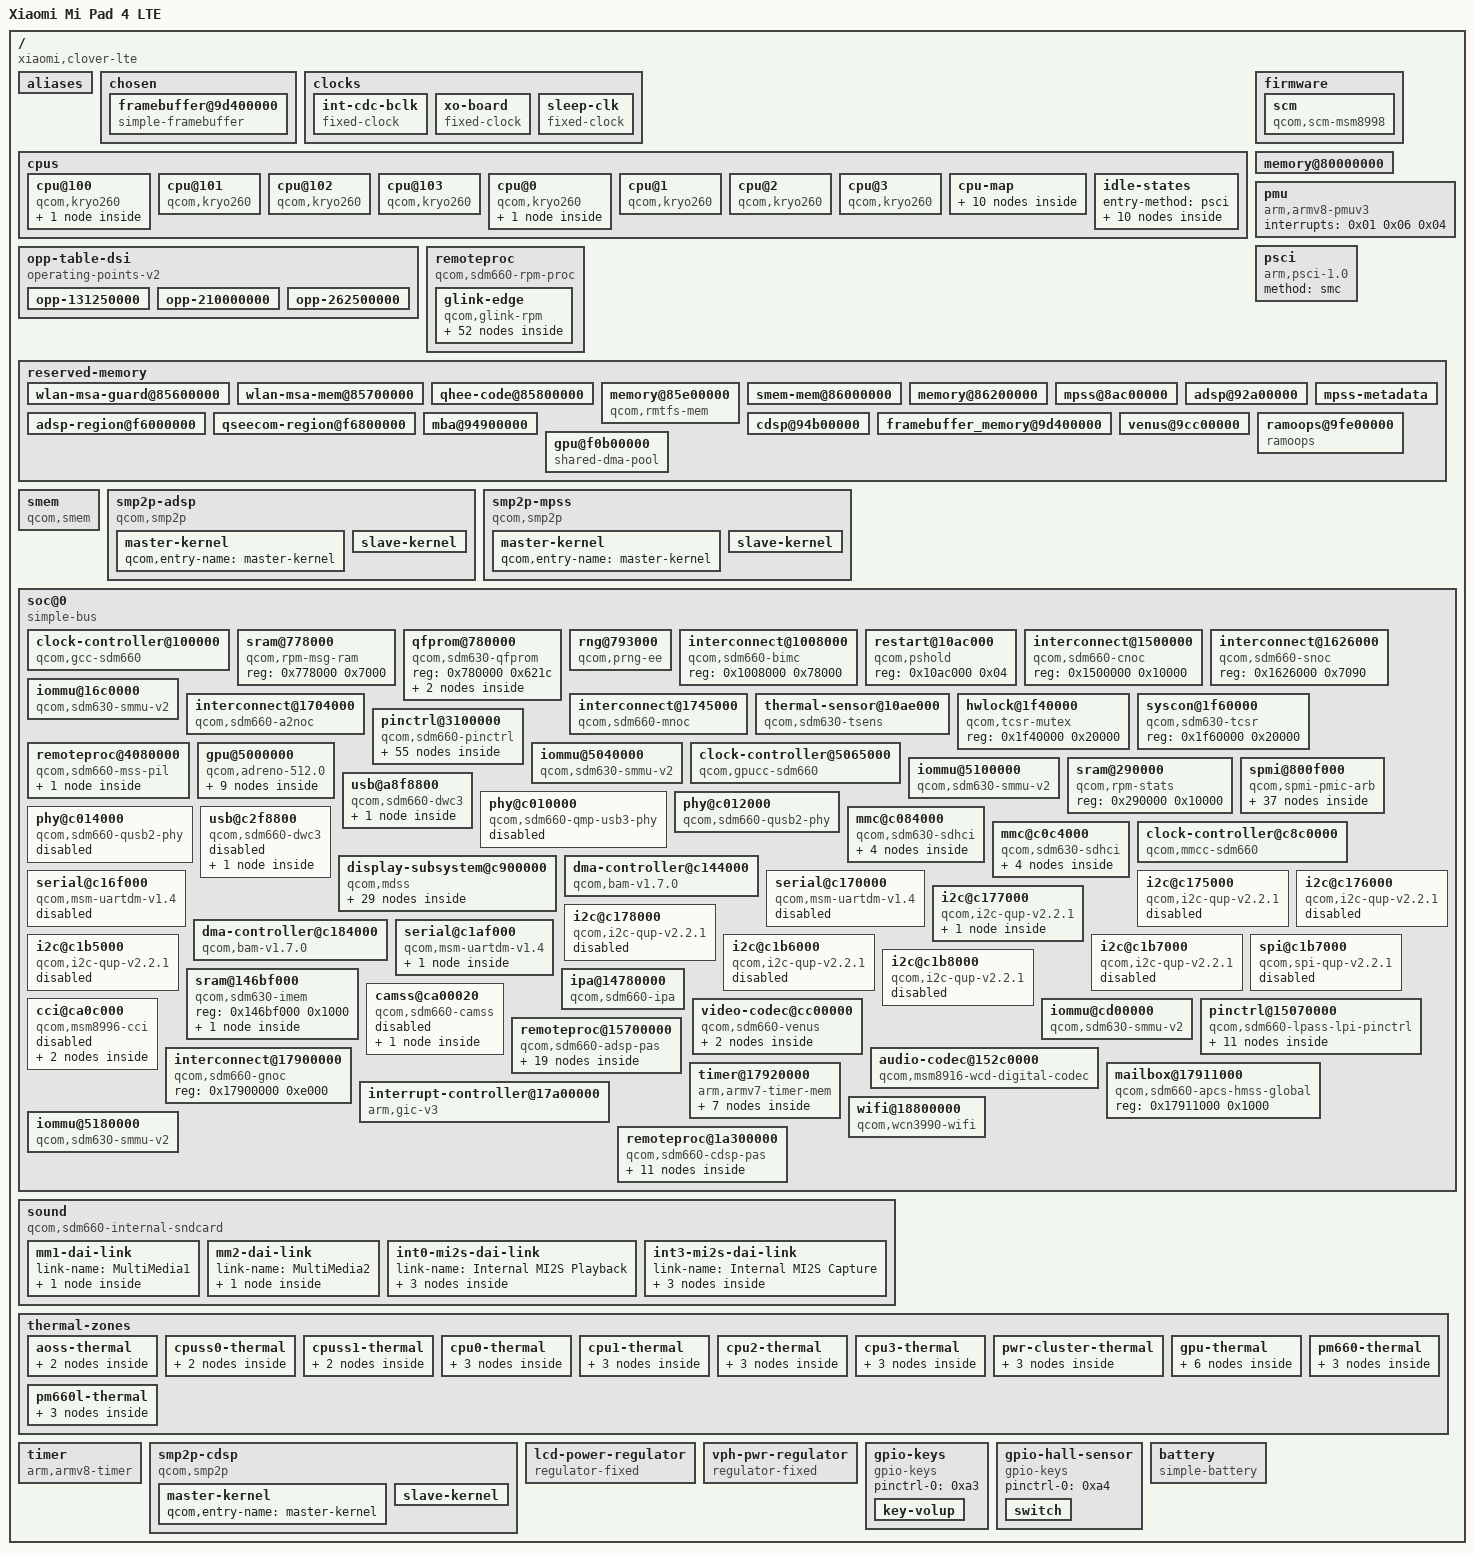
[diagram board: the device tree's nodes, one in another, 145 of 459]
/dts-v1/;

/ {
	interrupt-parent = <0x01>;
	#address-cells = <0x02>;
	#size-cells = <0x02>;
	model = "Xiaomi Mi Pad 4 LTE";
	compatible = "xiaomi,clover-lte", "qcom,sdm660";

	aliases {
		mmc1 = "/soc@0/mmc@c0c4000";
		mmc2 = "/soc@0/mmc@c084000";
		serial0 = "/soc@0/serial@c170000";
		serial1 = "/soc@0/serial@c1af000";
	};

	chosen {
		pureason = <0x00 0x80010>;
		linux,initrd-end = <0x00 0x83edd7f5>;
		linux,initrd-start = <0x00 0x83400000>;
		kaslr-seed = <0x00 0x00>;
		bootargs = "ignore_loglevel pmos_boot_uuid=98ecc23a-0614-4363-96cf-a99afc77ba68 pmos_root_uuid=408f1f31-18a8-40b9-8ee1-afe90d327c18 pmos_rootfsopts=defaults nocpuboost root=/dev/dm-0 dm=\"system none ro,0 1 android-verity /dev/mmcblk0p13\" androidboot.verifiedbootstate=orange androidboot.keymaster=1  androidboot.veritymode=enforcing androidboot.bootdevice=c0c4000.sdhci androidboot.serialno=<serial> androidboot.mode=charger androidboot.secureboot=1 androidboot.baseband=sdm mdss_mdp.panel=1:dsi:0:qcom,mdss_dsi_nt51021_boe_wuxga_video:config0:1:none:cfg:single_dsi";
		#address-cells = <0x02>;
		#size-cells = <0x02>;
		ranges;
		stdout-path = "serial0:115200n8";

		framebuffer@9d400000 {
			compatible = "simple-framebuffer";
			reg = <0x00 0x9d400000 0x00 0x8ca000>;
			width = <0x4b0>;
			height = <0x780>;
			stride = <0x12c0>;
			format = "a8r8g8b8";
			assigned-clocks = <0x02 0x70 0x02 0x74>;
			assigned-clock-rates = <0x11e1a300 0x124f800>;
			clocks = <0x02 0x60 0x02 0x61 0x02 0x74 0x02 0x70 0x02 0x01 0x02 0x83 0x02 0x62 0x02 0x63 0x02 0x77 0x02 0x75 0x02 0x71 0x02 0x6d>;
			power-domains = <0x03 0x00 0x02 0x02>;
		};
	};

	clocks {

		int-cdc-bclk {
			compatible = "fixed-clock";
			#clock-cells = <0x00>;
			clock-frequency = <0x177000>;
			clock-output-names = "int_cdc_bclk";
			phandle = <0x8a>;
		};

		xo-board {
			compatible = "fixed-clock";
			#clock-cells = <0x00>;
			clock-frequency = <0x124f800>;
			clock-output-names = "xo_board";
			phandle = <0x25>;
		};

		sleep-clk {
			compatible = "fixed-clock";
			#clock-cells = <0x00>;
			clock-frequency = <0x7ffc>;
			clock-output-names = "sleep_clk";
			phandle = <0x26>;
		};
	};

	cpus {
		#address-cells = <0x02>;
		#size-cells = <0x00>;

		cpu@100 {
			device_type = "cpu";
			compatible = "qcom,kryo260";
			reg = <0x00 0x100>;
			enable-method = "psci";
			cpu-idle-states = <0x04 0x05 0x06 0x07 0x08>;
			capacity-dmips-mhz = <0x400>;
			#cooling-cells = <0x02>;
			next-level-cache = <0x09>;
			phandle = <0x14>;

			l2-cache {
				compatible = "cache";
				cache-level = <0x02>;
				cache-unified;
				phandle = <0x09>;
			};
		};

		cpu@101 {
			device_type = "cpu";
			compatible = "qcom,kryo260";
			reg = <0x00 0x101>;
			enable-method = "psci";
			cpu-idle-states = <0x04 0x05 0x06 0x07 0x08>;
			capacity-dmips-mhz = <0x400>;
			#cooling-cells = <0x02>;
			next-level-cache = <0x09>;
			phandle = <0x15>;
		};

		cpu@102 {
			device_type = "cpu";
			compatible = "qcom,kryo260";
			reg = <0x00 0x102>;
			enable-method = "psci";
			cpu-idle-states = <0x04 0x05 0x06 0x07 0x08>;
			capacity-dmips-mhz = <0x400>;
			#cooling-cells = <0x02>;
			next-level-cache = <0x09>;
			phandle = <0x16>;
		};

		cpu@103 {
			device_type = "cpu";
			compatible = "qcom,kryo260";
			reg = <0x00 0x103>;
			enable-method = "psci";
			cpu-idle-states = <0x04 0x05 0x06 0x07 0x08>;
			capacity-dmips-mhz = <0x400>;
			#cooling-cells = <0x02>;
			next-level-cache = <0x09>;
			phandle = <0x17>;
		};

		cpu@0 {
			device_type = "cpu";
			compatible = "qcom,kryo260";
			reg = <0x00 0x00>;
			enable-method = "psci";
			cpu-idle-states = <0x0a 0x0b 0x0c 0x0d 0x0e>;
			capacity-dmips-mhz = <0x280>;
			#cooling-cells = <0x02>;
			next-level-cache = <0x0f>;
			phandle = <0x10>;

			l2-cache {
				compatible = "cache";
				cache-level = <0x02>;
				cache-unified;
				phandle = <0x0f>;
			};
		};

		cpu@1 {
			device_type = "cpu";
			compatible = "qcom,kryo260";
			reg = <0x00 0x01>;
			enable-method = "psci";
			cpu-idle-states = <0x0a 0x0b 0x0c 0x0d 0x0e>;
			capacity-dmips-mhz = <0x280>;
			#cooling-cells = <0x02>;
			next-level-cache = <0x0f>;
			phandle = <0x11>;
		};

		cpu@2 {
			device_type = "cpu";
			compatible = "qcom,kryo260";
			reg = <0x00 0x02>;
			enable-method = "psci";
			cpu-idle-states = <0x0a 0x0b 0x0c 0x0d 0x0e>;
			capacity-dmips-mhz = <0x280>;
			#cooling-cells = <0x02>;
			next-level-cache = <0x0f>;
			phandle = <0x12>;
		};

		cpu@3 {
			device_type = "cpu";
			compatible = "qcom,kryo260";
			reg = <0x00 0x03>;
			enable-method = "psci";
			cpu-idle-states = <0x0a 0x0b 0x0c 0x0d 0x0e>;
			capacity-dmips-mhz = <0x280>;
			#cooling-cells = <0x02>;
			next-level-cache = <0x0f>;
			phandle = <0x13>;
		};

		cpu-map {

			cluster0 {

				core0 {
					cpu = <0x10>;
				};

				core1 {
					cpu = <0x11>;
				};

				core2 {
					cpu = <0x12>;
				};

				core3 {
					cpu = <0x13>;
				};
			};

			cluster1 {

				core0 {
					cpu = <0x14>;
				};

				core1 {
					cpu = <0x15>;
				};

				core2 {
					cpu = <0x16>;
				};

				core3 {
					cpu = <0x17>;
				};
			};
		};

		idle-states {
			entry-method = "psci";

			cpu-sleep-0-0 {
				compatible = "arm,idle-state";
				idle-state-name = "pwr-retention";
				arm,psci-suspend-param = <0x40000002>;
				entry-latency-us = <0x152>;
				exit-latency-us = <0x1a7>;
				min-residency-us = <0xc8>;
				phandle = <0x0a>;
			};

			cpu-sleep-0-1 {
				compatible = "arm,idle-state";
				idle-state-name = "pwr-power-collapse";
				arm,psci-suspend-param = <0x40000003>;
				entry-latency-us = <0x203>;
				exit-latency-us = <0x71d>;
				min-residency-us = <0x3e8>;
				local-timer-stop;
				phandle = <0x0b>;
			};

			cpu-sleep-1-0 {
				compatible = "arm,idle-state";
				idle-state-name = "perf-retention";
				arm,psci-suspend-param = <0x40000002>;
				entry-latency-us = <0x9a>;
				exit-latency-us = <0x57>;
				min-residency-us = <0xc8>;
				phandle = <0x04>;
			};

			cpu-sleep-1-1 {
				compatible = "arm,idle-state";
				idle-state-name = "perf-power-collapse";
				arm,psci-suspend-param = <0x40000003>;
				entry-latency-us = <0x106>;
				exit-latency-us = <0x12d>;
				min-residency-us = <0x3e8>;
				local-timer-stop;
				phandle = <0x05>;
			};

			cluster-sleep-0-0 {
				compatible = "arm,idle-state";
				idle-state-name = "pwr-cluster-dynamic-retention";
				arm,psci-suspend-param = <0x400000f2>;
				entry-latency-us = <0x11c>;
				exit-latency-us = <0x180>;
				min-residency-us = <0x2703>;
				local-timer-stop;
				phandle = <0x0c>;
			};

			cluster-sleep-0-1 {
				compatible = "arm,idle-state";
				idle-state-name = "pwr-cluster-retention";
				arm,psci-suspend-param = <0x400000f3>;
				entry-latency-us = <0x152>;
				exit-latency-us = <0x1a7>;
				min-residency-us = <0x2703>;
				local-timer-stop;
				phandle = <0x0d>;
			};

			cluster-sleep-0-2 {
				compatible = "arm,idle-state";
				idle-state-name = "pwr-cluster-retention";
				arm,psci-suspend-param = <0x400000f4>;
				entry-latency-us = <0x203>;
				exit-latency-us = <0x71d>;
				min-residency-us = <0x2703>;
				local-timer-stop;
				phandle = <0x0e>;
			};

			cluster-sleep-1-0 {
				compatible = "arm,idle-state";
				idle-state-name = "perf-cluster-dynamic-retention";
				arm,psci-suspend-param = <0x400000f2>;
				entry-latency-us = <0x110>;
				exit-latency-us = <0x149>;
				min-residency-us = <0x2703>;
				local-timer-stop;
				phandle = <0x06>;
			};

			cluster-sleep-1-1 {
				compatible = "arm,idle-state";
				idle-state-name = "perf-cluster-retention";
				arm,psci-suspend-param = <0x400000f3>;
				entry-latency-us = <0x14c>;
				exit-latency-us = <0x170>;
				min-residency-us = <0x2703>;
				local-timer-stop;
				phandle = <0x07>;
			};

			cluster-sleep-1-2 {
				compatible = "arm,idle-state";
				idle-state-name = "perf-cluster-retention";
				arm,psci-suspend-param = <0x400000f4>;
				entry-latency-us = <0x221>;
				exit-latency-us = <0x649>;
				min-residency-us = <0x2703>;
				local-timer-stop;
				phandle = <0x08>;
			};
		};
	};

	firmware {

		scm {
			compatible = "qcom,scm-msm8998", "qcom,scm";
		};
	};

	memory@80000000 {
		device_type = "memory";
		reg = <0x00 0x80000000 0x00 0x80000000 0x01 0x00 0x00 0x7e4c0000>;
	};

	opp-table-dsi {
		compatible = "operating-points-v2";
		phandle = <0x59>;

		opp-131250000 {
			opp-hz = <0x00 0x7d2b750>;
			required-opps = <0x18>;
		};

		opp-210000000 {
			opp-hz = <0x00 0xc845880>;
			required-opps = <0x19>;
		};

		opp-262500000 {
			opp-hz = <0x00 0xfa56ea0>;
			required-opps = <0x1a>;
		};
	};

	pmu {
		compatible = "arm,armv8-pmuv3";
		interrupts = <0x01 0x06 0x04>;
	};

	psci {
		compatible = "arm,psci-1.0";
		method = "smc";
	};

	remoteproc {
		compatible = "qcom,sdm660-rpm-proc", "qcom,rpm-proc";

		glink-edge {
			compatible = "qcom,glink-rpm";
			interrupts = <0x00 0xa8 0x01>;
			qcom,rpm-msg-ram = <0x1b>;
			mboxes = <0x1c 0x00>;

			rpm-requests {
				compatible = "qcom,rpm-sdm660", "qcom,glink-smd-rpm";
				qcom,glink-channels = "rpm_requests";

				clock-controller {
					compatible = "qcom,rpmcc-sdm660", "qcom,rpmcc";
					#clock-cells = <0x01>;
					phandle = <0x28>;
				};

				power-controller {
					compatible = "qcom,sdm660-rpmpd";
					#power-domain-cells = <0x01>;
					operating-points-v2 = <0x1d>;
					phandle = <0x03>;

					opp-table {
						compatible = "operating-points-v2";
						phandle = <0x1d>;

						opp1 {
							opp-level = <0x10>;
						};

						opp2 {
							opp-level = <0x20>;
						};

						opp3 {
							opp-level = <0x30>;
						};

						opp4 {
							opp-level = <0x40>;
							phandle = <0x49>;
						};

						opp5 {
							opp-level = <0x80>;
							phandle = <0x18>;
						};

						opp6 {
							opp-level = <0xc0>;
							phandle = <0x19>;
						};

						opp7 {
							opp-level = <0x100>;
							phandle = <0x1a>;
						};

						opp8 {
							opp-level = <0x140>;
						};

						opp9 {
							opp-level = <0x180>;
							phandle = <0x58>;
						};
					};
				};

				regulators-0 {
					compatible = "qcom,rpm-pm660l-regulators";
					vdd_s1-supply = <0x1e>;
					vdd_s2-supply = <0x1e>;
					vdd_s3_s4-supply = <0x1e>;
					vdd_s5-supply = <0x1e>;
					vdd_s6-supply = <0x1e>;
					vdd_l1_l9_l10-supply = <0x1f>;
					vdd_l2-supply = <0x20>;
					vdd_l3_l5_l7_l8-supply = <0x20>;
					vdd_l4_l6-supply = <0x20>;
					vdd_bob-supply = <0x1e>;

					bob {
						regulator-min-microvolt = <0x325aa0>;
						regulator-max-microvolt = <0x36ee80>;
						regulator-enable-ramp-delay = <0x1f4>;
						regulator-ramp-delay = <0x00>;
						phandle = <0x20>;
					};

					s1 {
						regulator-min-microvolt = <0x112a88>;
						regulator-max-microvolt = <0x112a88>;
						regulator-enable-ramp-delay = <0xc8>;
						regulator-ramp-delay = <0x00>;
					};

					s2 {
						regulator-min-microvolt = <0x100590>;
						regulator-max-microvolt = <0x100590>;
						regulator-enable-ramp-delay = <0xc8>;
						regulator-ramp-delay = <0x00>;
						phandle = <0x1f>;
					};

					l1 {
						regulator-min-microvolt = "", "\f5";
						regulator-max-microvolt = <0xe1d48>;
						regulator-enable-ramp-delay = <0xfa>;
						regulator-ramp-delay = <0x00>;
						regulator-allow-set-load;
						phandle = <0x3f>;
					};

					l2 {
						regulator-min-microvolt = <0x192580>;
						regulator-max-microvolt = <0x2f4d60>;
						regulator-enable-ramp-delay = <0xfa>;
						regulator-allow-set-load;
						phandle = <0x48>;
					};

					l3 {
						regulator-min-microvolt = <0x2dc6c0>;
						regulator-max-microvolt = <0x2dc6c0>;
						regulator-enable-ramp-delay = <0xfa>;
						regulator-ramp-delay = <0x00>;
						regulator-min-microamp = <0xc8>;
						regulator-max-microamp = <0x927c0>;
						regulator-system-load = <0x186a0>;
						regulator-allow-set-load;
						regulator-always-on;
					};

					l4 {
						regulator-min-microvolt = <0x19f0a0>;
						regulator-max-microvolt = <0x2d0b40>;
						regulator-enable-ramp-delay = <0xfa>;
						regulator-ramp-delay = <0x00>;
						regulator-min-microamp = <0xc8>;
						regulator-max-microamp = <0x927c0>;
						regulator-system-load = <0x8b290>;
						regulator-allow-set-load;
						phandle = <0x4d>;
					};

					l5 {
						regulator-min-microvolt = <0x1b7740>;
						regulator-max-microvolt = <0x32c800>;
						regulator-enable-ramp-delay = <0xfa>;
						regulator-ramp-delay = <0x00>;
						regulator-allow-set-load;
						phandle = <0x47>;
					};

					l6 {
						regulator-min-microvolt = <0x1a0040>;
						regulator-max-microvolt = <0x328980>;
						regulator-enable-ramp-delay = <0xfa>;
						regulator-ramp-delay = <0x00>;
					};

					l7 {
						regulator-min-microvolt = <0x2932e0>;
						regulator-max-microvolt = <0x2faf08>;
						regulator-enable-ramp-delay = <0xfa>;
						regulator-ramp-delay = <0x00>;
						phandle = <0x3c>;
					};

					l8 {
						regulator-min-microvolt = <0x30d400>;
						regulator-max-microvolt = <0x33e140>;
						regulator-enable-ramp-delay = <0xfa>;
						regulator-ramp-delay = <0x00>;
					};

					l9 {
						status = "disabled";
					};

					l10 {
						status = "disabled";
					};
				};

				regulators-1 {
					compatible = "qcom,rpm-pm660-regulators";
					vdd_s1-supply = <0x1e>;
					vdd_s2-supply = <0x1e>;
					vdd_s3-supply = <0x1e>;
					vdd_s4-supply = <0x1e>;
					vdd_s5-supply = <0x1e>;
					vdd_s6-supply = <0x1e>;
					vdd_l1_l6_l7-supply = <0x21>;
					vdd_l2_l3-supply = <0x1f>;
					vdd_l5-supply = <0x1f>;
					vdd_l8_l9_l10_l11_l12_l13_l14-supply = <0x22>;
					vdd_l15_l16_l17_l18_l19-supply = <0x20>;

					s1 {
						status = "disabled";
					};

					s2 {
						status = "disabled";
					};

					s3 {
						status = "disabled";
					};

					s4 {
						regulator-min-microvolt = <0x1b8ac8>;
						regulator-max-microvolt = <0x1f20c0>;
						regulator-enable-ramp-delay = <0xc8>;
						regulator-ramp-delay = <0x00>;
						regulator-always-on;
						phandle = <0x22>;
					};

					s5 {
						regulator-min-microvolt = <0x12ad40>;
						regulator-max-microvolt = <0x149970>;
						regulator-enable-ramp-delay = <0xc8>;
						regulator-ramp-delay = <0x00>;
						phandle = <0x21>;
					};

					s6 {
						regulator-min-microvolt = <0x7b0c0>;
						regulator-max-microvolt = <0xf2300>;
						regulator-enable-ramp-delay = <0x96>;
						regulator-ramp-delay = <0x00>;
					};

					l1 {
						regulator-min-microvolt = <0x118c30>;
						regulator-max-microvolt = <0x1312d0>;
						regulator-enable-ramp-delay = <0xfa>;
						regulator-ramp-delay = <0x00>;
						regulator-allow-set-load;
						phandle = <0x5a>;
					};

					l2 {
						regulator-min-microvolt = <0xe7ef0>;
						regulator-max-microvolt = <0xf6950>;
						regulator-enable-ramp-delay = <0xfa>;
						regulator-ramp-delay = <0x00>;
					};

					l3 {
						regulator-min-microvolt = <0xe7ef0>;
						regulator-max-microvolt = <0xf6950>;
						regulator-enable-ramp-delay = <0xfa>;
						regulator-ramp-delay = <0x00>;
					};

					l5 {
						regulator-min-microvolt = <0x802c8>;
						regulator-max-microvolt = <0xe86c0>;
						regulator-enable-ramp-delay = <0xfa>;
						regulator-ramp-delay = <0x00>;
						phandle = <0x91>;
					};

					l6 {
						regulator-min-microvolt = <0x124f80>;
						regulator-max-microvolt = <0x14dfc0>;
						regulator-allow-set-load;
						regulator-enable-ramp-delay = <0xfa>;
						regulator-ramp-delay = <0x00>;
						phandle = <0x76>;
					};

					l7 {
						regulator-min-microvolt = <0x124f80>;
						regulator-max-microvolt = <0x124f80>;
						regulator-enable-ramp-delay = <0xfa>;
						regulator-ramp-delay = <0x00>;
					};

					l8 {
						regulator-min-microvolt = <0x1ab3f0>;
						regulator-max-microvolt = <0x1cfde0>;
						regulator-enable-ramp-delay = <0xfa>;
						regulator-ramp-delay = <0x00>;
						regulator-system-load = <0x4f588>;
						regulator-allow-set-load;
						phandle = <0x4e>;
					};

					l9 {
						regulator-min-microvolt = <0x1ab3f0>;
						regulator-max-microvolt = <0x1cfde0>;
						regulator-enable-ramp-delay = <0xfa>;
						regulator-ramp-delay = <0x00>;
						regulator-allow-set-load;
						phandle = <0x75>;
					};

					l10 {
						regulator-min-microvolt = <0x1b2920>;
						regulator-max-microvolt = <0x1dc130>;
						regulator-enable-ramp-delay = <0xfa>;
						regulator-ramp-delay = <0x00>;
						regulator-allow-set-load;
						regulator-system-load = <0x36b0>;
						phandle = <0x40>;
					};

					l11 {
						regulator-min-microvolt = <0x1b38c0>;
						regulator-max-microvolt = <0x1da9c0>;
						regulator-enable-ramp-delay = <0xfa>;
						regulator-ramp-delay = <0x00>;
						regulator-always-on;
						phandle = <0x6d>;
					};

					l12 {
						regulator-min-microvolt = <0x1b7740>;
						regulator-max-microvolt = <0x1da9c0>;
						regulator-enable-ramp-delay = <0xfa>;
						regulator-ramp-delay = <0x00>;
					};

					l13 {
						regulator-min-microvolt = <0x1b2920>;
						regulator-max-microvolt = <0x1dc130>;
						regulator-enable-ramp-delay = <0xfa>;
						regulator-ramp-delay = <0x00>;
						regulator-boot-on;
						regulator-always-on;
						phandle = <0x78>;
					};

					l14 {
						regulator-min-microvolt = <0x1a17b0>;
						regulator-max-microvolt = <0x1d0d80>;
						regulator-enable-ramp-delay = <0xfa>;
						regulator-ramp-delay = <0x00>;
					};

					l15 {
						regulator-min-microvolt = <0x192d50>;
						regulator-max-microvolt = <0x2d0b40>;
						regulator-enable-ramp-delay = <0xfa>;
						regulator-ramp-delay = <0x00>;
					};

					l16 {
						status = "disabled";
					};

					l17 {
						regulator-min-microvolt = <0x192580>;
						regulator-max-microvolt = <0x2d0b40>;
						regulator-enable-ramp-delay = <0xfa>;
						regulator-ramp-delay = <0x00>;
					};

					l18 {
						status = "disabled";
					};

					l19 {
						regulator-min-microvolt = <0x30d400>;
						regulator-max-microvolt = <0x33e140>;
						regulator-enable-ramp-delay = <0xfa>;
						regulator-ramp-delay = <0x00>;
						regulator-allow-set-load;
						phandle = <0x77>;
					};
				};
			};
		};
	};

	reserved-memory {
		#address-cells = <0x02>;
		#size-cells = <0x02>;
		ranges;

		wlan-msa-guard@85600000 {
			reg = <0x00 0x85600000 0x00 0x100000>;
			no-map;
		};

		wlan-msa-mem@85700000 {
			reg = <0x00 0x85700000 0x00 0x100000>;
			no-map;
			phandle = <0x90>;
		};

		qhee-code@85800000 {
			reg = <0x00 0x85800000 0x00 0x600000>;
			no-map;
		};

		memory@85e00000 {
			compatible = "qcom,rmtfs-mem";
			reg = <0x00 0x85e00000 0x00 0x200000>;
			no-map;
			qcom,client-id = <0x01>;
			qcom,vmid = <0x0f>;
		};

		smem-mem@86000000 {
			reg = <0x00 0x86000000 0x00 0x200000>;
			no-map;
			phandle = <0x23>;
		};

		memory@86200000 {
			reg = <0x00 0x86200000 0x00 0x3300000>;
			no-map;
		};

		mpss@8ac00000 {
			reg = <0x00 0x8ac00000 0x00 0x7e00000>;
			no-map;
			phandle = <0x2e>;
		};

		adsp@92a00000 {
			reg = <0x00 0x92a00000 0x00 0x1f00000>;
			no-map;
			phandle = <0x8d>;
		};

		adsp-region@f6000000 {
			reg = <0x00 0xf6000000 0x00 0x800000>;
			no-map;
		};

		qseecom-region@f6800000 {
			reg = <0x00 0xf6800000 0x00 0x1400000>;
			no-map;
		};

		mpss-metadata {
			alloc-ranges = <0x00 0xa0000000 0x00 0x20000000>;
			size = <0x00 0x4000>;
			no-map;
			phandle = <0x2f>;
		};

		mba@94900000 {
			reg = <0x00 0x94900000 0x00 0x200000>;
			no-map;
			phandle = <0x2d>;
		};

		cdsp@94b00000 {
			reg = <0x00 0x94b00000 0x00 0x600000>;
			no-map;
			phandle = <0x93>;
		};

		framebuffer_memory@9d400000 {
			reg = <0x00 0x9d400000 0x00 0x8ca000>;
			no-map;
		};

		venus@9cc00000 {
			reg = <0x00 0x9cc00000 0x00 0x800000>;
			no-map;
			phandle = <0x88>;
		};

		ramoops@9fe00000 {
			compatible = "ramoops";
			reg = <0x00 0x9fe00000 0x00 0x100000>;
			console-size = <0x80000>;
			record-size = <0x1000>;
			ftrace-size = <0x1000>;
			pmsg-size = <0x8000>;
		};

		gpu@f0b00000 {
			compatible = "shared-dma-pool";
			reg = <0x00 0xf0b00000 0x00 0x2000>;
			no-map;
			phandle = <0x35>;
		};
	};

	smem {
		compatible = "qcom,smem";
		memory-region = <0x23>;
		hwlocks = <0x24 0x03>;
	};

	smp2p-adsp {
		compatible = "qcom,smp2p";
		qcom,smem = <0x1bb 0x1ad>;
		interrupts = <0x00 0x9e 0x01>;
		mboxes = <0x1c 0x0a>;
		qcom,local-pid = <0x00>;
		qcom,remote-pid = <0x02>;

		master-kernel {
			qcom,entry-name = "master-kernel";
			#qcom,smem-state-cells = <0x01>;
			phandle = <0x8e>;
		};

		slave-kernel {
			qcom,entry-name = "slave-kernel";
			interrupt-controller;
			#interrupt-cells = <0x02>;
			phandle = <0x8c>;
		};
	};

	smp2p-mpss {
		compatible = "qcom,smp2p";
		qcom,smem = <0x1b3 0x1ac>;
		interrupts = <0x00 0x1c3 0x01>;
		mboxes = <0x1c 0x0e>;
		qcom,local-pid = <0x00>;
		qcom,remote-pid = <0x01>;

		master-kernel {
			qcom,entry-name = "master-kernel";
			#qcom,smem-state-cells = <0x01>;
			phandle = <0x2b>;
		};

		slave-kernel {
			qcom,entry-name = "slave-kernel";
			interrupt-controller;
			#interrupt-cells = <0x02>;
			phandle = <0x2a>;
		};
	};

	soc@0 {
		#address-cells = <0x01>;
		#size-cells = <0x01>;
		ranges = <0x00 0x00 0x00 0xffffffff>;
		compatible = "simple-bus";

		clock-controller@100000 {
			compatible = "qcom,gcc-sdm660";
			#clock-cells = <0x01>;
			#reset-cells = <0x01>;
			#power-domain-cells = <0x01>;
			reg = <0x100000 0x94000>;
			clock-names = "xo", "sleep_clk";
			clocks = <0x25 0x26>;
			phandle = <0x27>;
		};

		sram@778000 {
			compatible = "qcom,rpm-msg-ram";
			reg = <0x778000 0x7000>;
			phandle = <0x1b>;
		};

		qfprom@780000 {
			compatible = "qcom,sdm630-qfprom", "qcom,qfprom";
			reg = <0x780000 0x621c>;
			#address-cells = <0x01>;
			#size-cells = <0x01>;

			hstx-trim@240 {
				reg = <0x243 0x01>;
				bits = <0x01 0x03>;
				phandle = <0x3e>;
			};

			gpu-speed-bin@41a0 {
				reg = <0x41a2 0x02>;
				bits = <0x05 0x08>;
				phandle = <0x32>;
			};
		};

		rng@793000 {
			compatible = "qcom,prng-ee";
			reg = <0x793000 0x1000>;
			clocks = <0x27 0x47>;
			clock-names = "core";
		};

		interconnect@1008000 {
			compatible = "qcom,sdm660-bimc";
			reg = <0x1008000 0x78000>;
			#interconnect-cells = <0x01>;
			phandle = <0x33>;
		};

		restart@10ac000 {
			compatible = "qcom,pshold";
			reg = <0x10ac000 0x04>;
		};

		interconnect@1500000 {
			compatible = "qcom,sdm660-cnoc";
			reg = <0x1500000 0x10000>;
			#interconnect-cells = <0x01>;
			phandle = <0x43>;
		};

		interconnect@1626000 {
			compatible = "qcom,sdm660-snoc";
			reg = <0x1626000 0x7090>;
			#interconnect-cells = <0x01>;
			phandle = <0x83>;
		};

		iommu@16c0000 {
			compatible = "qcom,sdm630-smmu-v2", "qcom,smmu-v2";
			reg = <0x16c0000 0x40000>;
			#global-interrupts = <0x02>;
			#iommu-cells = <0x01>;
			interrupts = <0x00 0xe5 0x04 0x00 0xe7 0x04 0x00 0x175 0x04 0x00 0x176 0x08 0x00 0x177 0x08 0x00 0x178 0x08 0x00 0x179 0x08 0x00 0x17a 0x08 0x00 0x1ce 0x04 0x00 0x1cf 0x04 0x00 0x1d0 0x04 0x00 0x1d1 0x04 0x00 0x1d2 0x04 0x00 0x1d3 0x04 0x00 0x161 0x04 0x00 0x162 0x04 0x00 0x163 0x04 0x00 0x164 0x04 0x00 0x165 0x04 0x00 0x166 0x04 0x00 0x167 0x04 0x00 0x168 0x04 0x00 0x1ba 0x04 0x00 0x1bb 0x04 0x00 0x1bc 0x04 0x00 0x1bf 0x04 0x00 0x1d4 0x04 0x00 0x1d5 0x04 0x00 0x1d8 0x04 0x00 0x1d9 0x04 0x00 0x1da 0x04>;
			phandle = <0x84>;
		};

		interconnect@1704000 {
			compatible = "qcom,sdm660-a2noc";
			reg = <0x1704000 0xc100>;
			#interconnect-cells = <0x01>;
			clock-names = "ipa", "ufs_axi", "aggre2_ufs_axi", "aggre2_usb3_axi", "cfg_noc_usb2_axi";
			clocks = <0x28 0x44 0x27 0x50 0x27 0x14 0x27 0x15 0x27 0x30>;
			phandle = <0x41>;
		};

		interconnect@1745000 {
			compatible = "qcom,sdm660-mnoc";
			reg = <0x1745000 0xa010>;
			#interconnect-cells = <0x01>;
			clock-names = "iface";
			clocks = <0x02 0x00>;
			phandle = <0x53>;
		};

		thermal-sensor@10ae000 {
			compatible = "qcom,sdm630-tsens", "qcom,tsens-v2";
			reg = <0x10ae000 0x1000 0x10ad000 0x1000>;
			#qcom,sensors = <0x0e>;
			interrupts = <0x00 0xb8 0x04 0x00 0x1ae 0x04>;
			interrupt-names = "uplow", "critical";
			#thermal-sensor-cells = <0x01>;
			phandle = <0x9d>;
		};

		hwlock@1f40000 {
			compatible = "qcom,tcsr-mutex";
			reg = <0x1f40000 0x20000>;
			#hwlock-cells = <0x01>;
			phandle = <0x24>;
		};

		syscon@1f60000 {
			compatible = "qcom,sdm630-tcsr", "syscon";
			reg = <0x1f60000 0x20000>;
			phandle = <0x2c>;
		};

		pinctrl@3100000 {
			compatible = "qcom,sdm660-pinctrl";
			reg = <0x3100000 0x400000 0x3500000 0x400000 0x3900000 0x400000>;
			reg-names = "south", "center", "north";
			interrupts = <0x00 0xd0 0x04>;
			gpio-controller;
			gpio-ranges = <0x29 0x00 0x00 0x72>;
			#gpio-cells = <0x02>;
			interrupt-controller;
			#interrupt-cells = <0x02>;
			gpio-reserved-ranges = <0x00 0x04>;
			phandle = <0x29>;

			blsp1-uart1-default-state {
				pins = "gpio0", "gpio1", "gpio2", "gpio3";
				function = "blsp_uart1";
				drive-strength = <0x02>;
				bias-disable;
				phandle = <0x64>;
			};

			blsp1-uart1-sleep-state {
				pins = "gpio0", "gpio1", "gpio2", "gpio3";
				function = "gpio";
				drive-strength = <0x02>;
				bias-disable;
				phandle = <0x65>;
			};

			blsp1-uart2-default-state {
				pins = "gpio4", "gpio5";
				function = "blsp_uart2";
				drive-strength = <0x02>;
				bias-disable;
				phandle = <0x66>;
			};

			blsp2-uart1-active-state {
				phandle = <0x73>;

				tx-rts-pins {
					pins = "gpio16", "gpio19";
					function = "blsp_uart5";
					drive-strength = <0x02>;
					bias-disable;
				};

				rx-pins {
					pins = "gpio17";
					function = "blsp_uart5";
					drive-strength = <0x02>;
					bias-pull-up;
				};

				cts-pins {
					pins = "gpio18";
					function = "blsp_uart5";
					drive-strength = <0x02>;
					bias-pull-down;
				};
			};

			blsp2-uart1-sleep-state {
				phandle = <0x74>;

				tx-pins {
					pins = "gpio16";
					function = "gpio";
					drive-strength = <0x02>;
					bias-pull-up;
				};

				rx-cts-rts-pins {
					pins = "gpio17", "gpio18", "gpio19";
					function = "gpio";
					drive-strength = <0x02>;
					bias-disable;
				};
			};

			i2c1-default-state {
				pins = "gpio2", "gpio3";
				function = "blsp_i2c1";
				drive-strength = <0x02>;
				bias-disable;
				phandle = <0x67>;
			};

			i2c1-sleep-state {
				pins = "gpio2", "gpio3";
				function = "blsp_i2c1";
				drive-strength = <0x02>;
				bias-pull-up;
				phandle = <0x68>;
			};

			i2c2-default-state {
				pins = "gpio6", "gpio7";
				function = "blsp_i2c2";
				drive-strength = <0x02>;
				bias-disable;
				phandle = <0x69>;
			};

			i2c2-sleep-state {
				pins = "gpio6", "gpio7";
				function = "blsp_i2c2";
				drive-strength = <0x02>;
				bias-pull-up;
				phandle = <0x6a>;
			};

			i2c3-default-state {
				pins = "gpio10", "gpio11";
				function = "blsp_i2c3";
				drive-strength = <0x02>;
				bias-disable;
				phandle = <0x6b>;
			};

			i2c3-sleep-state {
				pins = "gpio10", "gpio11";
				function = "blsp_i2c3";
				drive-strength = <0x02>;
				bias-pull-up;
				phandle = <0x6c>;
			};

			i2c4-default-state {
				pins = "gpio14", "gpio15";
				function = "blsp_i2c4";
				drive-strength = <0x02>;
				bias-disable;
				phandle = <0x70>;
			};

			i2c4-sleep-state {
				pins = "gpio14", "gpio15";
				function = "blsp_i2c4";
				drive-strength = <0x02>;
				bias-pull-up;
				phandle = <0x71>;
			};

			i2c5-default-state {
				pins = "gpio18", "gpio19";
				function = "blsp_i2c5";
				drive-strength = <0x02>;
				bias-disable;
				phandle = <0x79>;
			};

			i2c5-sleep-state {
				pins = "gpio18", "gpio19";
				function = "blsp_i2c5";
				drive-strength = <0x02>;
				bias-pull-up;
				phandle = <0x7a>;
			};

			i2c6-default-state {
				pins = "gpio22", "gpio23";
				function = "blsp_i2c6";
				drive-strength = <0x02>;
				bias-disable;
				phandle = <0x7b>;
			};

			i2c6-sleep-state {
				pins = "gpio22", "gpio23";
				function = "blsp_i2c6";
				drive-strength = <0x02>;
				bias-pull-up;
				phandle = <0x7c>;
			};

			i2c7-default-state {
				pins = "gpio26", "gpio27";
				function = "blsp_i2c7";
				drive-strength = <0x02>;
				bias-disable;
				phandle = <0x7d>;
			};

			i2c7-sleep-state {
				pins = "gpio26", "gpio27";
				function = "blsp_i2c7";
				drive-strength = <0x02>;
				bias-pull-up;
				phandle = <0x7e>;
			};

			i2c8-default-state {
				pins = "gpio30", "gpio31";
				function = "blsp_i2c8_a";
				drive-strength = <0x02>;
				bias-disable;
				phandle = <0x81>;
			};

			i2c8-sleep-state {
				pins = "gpio30", "gpio31";
				function = "blsp_i2c8_a";
				drive-strength = <0x02>;
				bias-pull-up;
				phandle = <0x82>;
			};

			cci0-default-state {
				pins = "gpio36", "gpio37";
				function = "cci_i2c";
				bias-pull-up;
				drive-strength = <0x02>;
				phandle = <0x86>;
			};

			cci1-default-state {
				pins = "gpio38", "gpio39";
				function = "cci_i2c";
				bias-pull-up;
				drive-strength = <0x02>;
				phandle = <0x87>;
			};

			sdc1-on-state {
				phandle = <0x4b>;

				clk-pins {
					pins = "sdc1_clk";
					bias-disable;
					drive-strength = <0x10>;
				};

				cmd-pins {
					pins = "sdc1_cmd";
					bias-pull-up;
					drive-strength = <0x0a>;
				};

				data-pins {
					pins = "sdc1_data";
					bias-pull-up;
					drive-strength = <0x0a>;
				};

				rclk-pins {
					pins = "sdc1_rclk";
					bias-pull-down;
				};
			};

			sdc1-off-state {
				phandle = <0x4c>;

				clk-pins {
					pins = "sdc1_clk";
					bias-disable;
					drive-strength = <0x02>;
				};

				cmd-pins {
					pins = "sdc1_cmd";
					bias-pull-up;
					drive-strength = <0x02>;
				};

				data-pins {
					pins = "sdc1_data";
					bias-pull-up;
					drive-strength = <0x02>;
				};

				rclk-pins {
					pins = "sdc1_rclk";
					bias-pull-down;
				};
			};

			sdc2-on-state {
				phandle = <0x45>;

				clk-pins {
					pins = "sdc2_clk";
					bias-disable;
					drive-strength = <0x10>;
				};

				cmd-pins {
					pins = "sdc2_cmd";
					bias-pull-up;
					drive-strength = <0x0a>;
				};

				data-pins {
					pins = "sdc2_data";
					bias-pull-up;
					drive-strength = <0x0a>;
				};

				sd-cd-pins {
					pins = "gpio54";
					function = "gpio";
					bias-pull-up;
					drive-strength = <0x02>;
				};
			};

			sdc2-off-state {
				phandle = <0x46>;

				clk-pins {
					pins = "sdc2_clk";
					bias-disable;
					drive-strength = <0x02>;
				};

				cmd-pins {
					pins = "sdc2_cmd";
					bias-pull-up;
					drive-strength = <0x02>;
				};

				data-pins {
					pins = "sdc2_data";
					bias-pull-up;
					drive-strength = <0x02>;
				};

				sd-cd-pins {
					pins = "gpio54";
					function = "gpio";
					bias-disable;
					drive-strength = <0x02>;
				};
			};

			spi7-default-state {
				pins = "gpio24", "gpio25", "gpio26", "gpio27";
				function = "blsp_spi7";
				drive-strength = <0x06>;
				bias-disable;
				phandle = <0x7f>;
			};

			spi7-sleep-state {
				pins = "gpio24", "gpio25", "gpio26", "gpio27";
				function = "blsp_spi7";
				drive-strength = <0x06>;
				bias-disable;
				phandle = <0x80>;
			};

			mdss-dsi-reset-state {
				pins = "gpio62";
				function = "gpio";
				drive-strength = <0x08>;
				bias-disable;
				phandle = <0x5f>;
			};

			mdss-vsync-active-state {
				pins = "gpio59";
				function = "mdp_vsync";
				drive-strength = <0x02>;
				bias-pull-down;
				phandle = <0x60>;
			};

			gpio-hall-sensor-default-state {
				pins = "gpio75";
				function = "gpio";
				drive-strength = <0x06>;
				bias-pull-up;
				phandle = <0xa4>;
			};

			ts-int-active-state {
				pins = "gpio67";
				function = "gpio";
				drive-strength = <0x08>;
				bias-pull-up;
				phandle = <0x6e>;
			};

			ts-rst-state {
				pins = "gpio66";
				function = "gpio";
				drive-strength = <0x08>;
				bias-pull-up;
				phandle = <0x6f>;
			};
		};

		remoteproc@4080000 {
			compatible = "qcom,sdm660-mss-pil";
			reg = <0x4080000 0x100 0x4180000 0x40>;
			reg-names = "qdsp6", "rmb";
			interrupts-extended = <0x01 0x00 0x1c0 0x01 0x2a 0x00 0x01 0x2a 0x01 0x01 0x2a 0x02 0x01 0x2a 0x03 0x01 0x2a 0x07 0x01>;
			interrupt-names = "wdog", "fatal", "ready", "handover", "stop-ack", "shutdown-ack";
			clocks = <0x27 0x40 0x27 0x18 0x27 0x2f 0x27 0x7c 0x27 0x44 0x27 0x42 0x28 0x08 0x28 0x00>;
			clock-names = "iface", "bus", "mem", "gpll0_mss", "snoc_axi", "mnoc_axi", "qdss", "xo";
			qcom,smem-states = <0x2b 0x00>;
			qcom,smem-state-names = "stop";
			resets = <0x27 0x09>;
			reset-names = "mss_restart";
			qcom,halt-regs = <0x2c 0x3000 0x5000 0x4000>;
			power-domains = <0x03 0x00 0x03 0x03>;
			power-domain-names = "cx", "mx";
			memory-region = <0x2d 0x2e 0x2f>;
			status = "okay";
			firmware-name = "mba.mbn", "modem.mdt";
			phandle = <0x85>;

			glink-edge {
				interrupts = <0x00 0x1c4 0x01>;
				label = "modem";
				qcom,remote-pid = <0x01>;
				mboxes = <0x1c 0x0f>;
			};
		};

		gpu@5000000 {
			compatible = "qcom,adreno-512.0", "qcom,adreno";
			reg = <0x5000000 0x40000>;
			reg-names = "kgsl_3d0_reg_memory";
			interrupts = <0x00 0x12c 0x04>;
			clocks = <0x27 0x37 0x30 0x08 0x27 0x16 0x27 0x36 0x30 0x06 0x30 0x07>;
			clock-names = "iface", "rbbmtimer", "mem", "mem_iface", "rbcpr", "core";
			power-domains = <0x03 0x03>;
			iommus = <0x31 0x00>;
			nvmem-cells = <0x32>;
			nvmem-cell-names = "speed_bin";
			interconnects = <0x33 0x01 0x33 0x05>;
			interconnect-names = "gfx-mem";
			operating-points-v2 = <0x34>;
			#cooling-cells = <0x02>;
			status = "okay";
			phandle = <0x9f>;

			opp-table {
				compatible = "operating-points-v2";
				phandle = <0x34>;

				opp-588000000 {
					opp-hz = <0x00 0x230c2b00>;
					opp-level = <0x100>;
					opp-peak-kBps = <0x2ee000>;
					opp-supported-hw = <0x70>;
				};

				opp-465000000 {
					opp-hz = <0x00 0x1bb75640>;
					opp-level = <0xc0>;
					opp-peak-kBps = <0x2990a0>;
					opp-supported-hw = <0x78>;
				};

				opp-370000000 {
					opp-hz = <0x00 0x160dc080>;
					opp-level = <0x80>;
					opp-peak-kBps = <0x2162e0>;
					opp-supported-hw = <0xff>;
				};

				opp-160000000 {
					opp-hz = <0x00 0x9896800>;
					opp-level = <0x30>;
					opp-peak-kBps = <0x124f80>;
					opp-supported-hw = <0xff>;
				};

				opp-19200000 {
					opp-hz = <0x00 0x124f800>;
					opp-level = <0x30>;
					opp-peak-kBps = <0x124f80>;
					opp-supported-hw = <0xff>;
				};

				opp-430000000 {
					opp-hz = <0x00 0x19a14780>;
					opp-level = <0xc0>;
					opp-peak-kBps = <0x2990a0>;
					opp-supported-hw = <0x04>;
				};

				opp-266000000 {
					opp-hz = <0x00 0xfdad680>;
					opp-level = <0x40>;
					opp-peak-kBps = <0x192580>;
					opp-supported-hw = <0xff>;
				};
			};

			zap-shader {
				memory-region = <0x35>;
				firmware-name = "a512_zap.mdt";
			};
		};

		iommu@5040000 {
			compatible = "qcom,sdm630-smmu-v2", "qcom,adreno-smmu", "qcom,smmu-v2";
			reg = <0x5040000 0x10000>;
			power-domains = <0x30 0x01>;
			clocks = <0x27 0x37 0x27 0x16 0x27 0x36>;
			clock-names = "iface", "mem", "mem_iface";
			#global-interrupts = <0x02>;
			#iommu-cells = <0x01>;
			interrupts = <0x00 0xe5 0x04 0x00 0xe7 0x04 0x00 0x149 0x04 0x00 0x14a 0x04 0x00 0x14b 0x04 0x00 0x14c 0x04 0x00 0x74 0x04 0x00 0x75 0x04 0x00 0x15d 0x04 0x00 0x15e 0x04>;
			phandle = <0x31>;
		};

		clock-controller@5065000 {
			compatible = "qcom,gpucc-sdm660";
			#clock-cells = <0x01>;
			#reset-cells = <0x01>;
			#power-domain-cells = <0x01>;
			reg = <0x5065000 0x9038>;
			clocks = <0x25 0x27 0x38 0x27 0x39>;
			clock-names = "xo", "gcc_gpu_gpll0_clk", "gcc_gpu_gpll0_div_clk";
			phandle = <0x30>;
		};

		iommu@5100000 {
			compatible = "qcom,sdm630-smmu-v2", "qcom,smmu-v2";
			reg = <0x5100000 0x40000>;
			#iommu-cells = <0x01>;
			clocks = <0x27 0x83>;
			clock-names = "bus";
			power-domains = <0x27 0x05>;
			#global-interrupts = <0x02>;
			interrupts = <0x00 0xe5 0x04 0x00 0xe7 0x04 0x00 0xe2 0x04 0x00 0x189 0x04 0x00 0x18a 0x04 0x00 0x18b 0x04 0x00 0x18c 0x04 0x00 0x18d 0x04 0x00 0x18e 0x04 0x00 0x18f 0x04 0x00 0x190 0x04 0x00 0x191 0x04 0x00 0x192 0x04 0x00 0x193 0x04 0x00 0x89 0x04 0x00 0xe0 0x04 0x00 0xe1 0x04 0x00 0x136 0x04 0x00 0x194 0x04>;
			phandle = <0x8f>;
		};

		sram@290000 {
			compatible = "qcom,rpm-stats";
			reg = <0x290000 0x10000>;
		};

		spmi@800f000 {
			compatible = "qcom,spmi-pmic-arb";
			reg = <0x800f000 0x1000 0x8400000 0x1000000 0x9400000 0x1000000 0xa400000 0x220000 0x800a000 0x3000>;
			reg-names = "core", "chnls", "obsrvr", "intr", "cnfg";
			interrupt-names = "periph_irq";
			interrupts = <0x00 0x146 0x04>;
			qcom,ee = <0x00>;
			qcom,channel = <0x00>;
			#address-cells = <0x02>;
			#size-cells = <0x00>;
			interrupt-controller;
			#interrupt-cells = <0x04>;

			pmic@0 {
				compatible = "qcom,pm660", "qcom,spmi-pmic";
				reg = <0x00 0x00>;
				#address-cells = <0x01>;
				#size-cells = <0x00>;

				rtc@6000 {
					compatible = "qcom,pm8941-rtc";
					reg = <0x6000 0x6100>;
					reg-names = "rtc", "alarm";
					interrupts = <0x00 0x61 0x01 0x01>;
				};

				pon@800 {
					compatible = "qcom,pm8998-pon";
					reg = <0x800>;
					mode-bootloader = <0x02>;
					mode-recovery = <0x01>;

					pwrkey {
						compatible = "qcom,pm8941-pwrkey";
						interrupts = <0x00 0x08 0x00 0x03>;
						debounce = <0x3d09>;
						bias-pull-up;
						linux,code = <0x74>;
						status = "okay";
					};

					resin {
						compatible = "qcom,pm8941-resin";
						interrupts = <0x00 0x08 0x01 0x03>;
						debounce = <0x3d09>;
						bias-pull-up;
						status = "okay";
						linux,code = <0x72>;
					};
				};

				charger@1000 {
					compatible = "qcom,pm660-charger";
					reg = <0x1000>;
					interrupts = <0x00 0x13 0x04 0x03 0x00 0x12 0x02 0x03 0x00 0x16 0x01 0x01 0x00 0x13 0x06 0x01>;
					interrupt-names = "usb-plugin", "bat-ov", "wdog-bark", "usbin-icl-change";
					io-channels = <0x36 0x03 0x36 0x04>;
					io-channel-names = "usbin_i", "usbin_v";
					status = "okay";
					monitored-battery = <0x37>;
					phandle = <0x39>;
				};

				temp-alarm@2400 {
					compatible = "qcom,spmi-temp-alarm";
					reg = <0x2400>;
					interrupts = <0x00 0x24 0x00 0x01>;
					io-channels = <0x38 0x06>;
					io-channel-names = "thermal";
					#thermal-sensor-cells = <0x00>;
					phandle = <0xa0>;
				};

				adc@3100 {
					compatible = "qcom,spmi-adc-rev2";
					reg = <0x3100>;
					interrupts = <0x00 0x31 0x00 0x01>;
					#address-cells = <0x01>;
					#size-cells = <0x00>;
					#io-channel-cells = <0x01>;
					phandle = <0x38>;

					channel@0 {
						reg = <0x00>;
						qcom,decimation = <0x400>;
						qcom,pre-scaling = <0x01 0x01>;
						label = "ref_gnd";
					};

					channel@1 {
						reg = <0x01>;
						qcom,decimation = <0x400>;
						qcom,pre-scaling = <0x01 0x01>;
						label = "vref_1p25";
					};

					channel@6 {
						reg = <0x06>;
						qcom,decimation = <0x400>;
						qcom,pre-scaling = <0x01 0x01>;
						label = "die_temp";
					};

					channel@4c {
						reg = <0x4c>;
						qcom,pre-scaling = <0x01 0x01>;
						qcom,decimation = <0x400>;
						qcom,hw-settle-time = <0xc8>;
						qcom,ratiometric;
						label = "xo_therm";
					};

					channel@4d {
						reg = <0x4d>;
						qcom,pre-scaling = <0x01 0x01>;
						qcom,decimation = <0x400>;
						qcom,hw-settle-time = <0xc8>;
						qcom,ratiometric;
						label = "msm_therm";
					};

					channel@4e {
						reg = <0x4e>;
						qcom,pre-scaling = <0x01 0x01>;
						qcom,decimation = <0x400>;
						qcom,hw-settle-time = <0xc8>;
						qcom,ratiometric;
						label = "emmc_therm";
					};

					channel@4f {
						reg = <0x4f>;
						qcom,pre-scaling = <0x01 0x01>;
						qcom,decimation = <0x400>;
						qcom,hw-settle-time = <0xc8>;
						qcom,ratiometric;
						label = "pa_therm0";
					};

					channel@50 {
						reg = <0x50>;
						qcom,pre-scaling = <0x01 0x01>;
						qcom,decimation = <0x400>;
						qcom,hw-settle-time = <0xc8>;
						qcom,ratiometric;
						label = "pa_therm1";
					};

					channel@51 {
						reg = <0x51>;
						qcom,pre-scaling = <0x01 0x01>;
						qcom,decimation = <0x400>;
						qcom,hw-settle-time = <0xc8>;
						qcom,ratiometric;
						label = "quiet_therm";
					};

					channel@83 {
						reg = <0x83>;
						qcom,decimation = <0x400>;
						qcom,pre-scaling = <0x01 0x03>;
						label = "vph_pwr";
					};

					channel@85 {
						reg = <0x85>;
						qcom,decimation = <0x400>;
						qcom,pre-scaling = <0x01 0x03>;
						label = "vcoin";
					};
				};

				battery@4000 {
					compatible = "qcom,pmi8998-fg";
					reg = <0x4000>;
					interrupts = <0x00 0x40 0x03 0x01>;
					interrupt-names = "soc-delta";
					status = "okay";
					monitored-battery = <0x37>;
					power-supplies = <0x39>;
				};

				adc@4500 {
					compatible = "qcom,pm660-rradc";
					reg = <0x4500>;
					#io-channel-cells = <0x01>;
					status = "okay";
					phandle = <0x36>;
				};

				gpio@c000 {
					compatible = "qcom,pm660-gpio", "qcom,spmi-gpio";
					reg = <0xc000>;
					gpio-controller;
					gpio-ranges = <0x3a 0x00 0x00 0x0d>;
					#gpio-cells = <0x02>;
					interrupt-controller;
					#interrupt-cells = <0x02>;
					phandle = <0x3a>;
				};
			};

			pmic@1 {
				compatible = "qcom,pm660", "qcom,spmi-pmic";
				reg = <0x01 0x00>;
				#address-cells = <0x01>;
				#size-cells = <0x00>;

				vibrator@c000 {
					compatible = "qcom,pmi8998-haptics", "qcom,spmi-haptics";
					reg = <0xc000>;
					interrupts = <0x01 0xc0 0x00 0x03 0x01 0xc0 0x01 0x03>;
					interrupt-names = "short", "play";
					qcom,actuator-type = <0x00>;
					qcom,brake-pattern = <0x03 0x03 0x00 0x00>;
					qcom,play-mode = <0x01>;
					qcom,wave-play-rate-us = <0x1a0b>;
					qcom,wave-shape = <0x01>;
					status = "disabled";
				};

				regulators {
					compatible = "qcom,pm660-regulators";
				};
			};

			pmic@2 {
				compatible = "qcom,pm660l", "qcom,spmi-pmic";
				reg = <0x02 0x00>;
				#address-cells = <0x01>;
				#size-cells = <0x00>;

				temp-alarm@2400 {
					compatible = "qcom,spmi-temp-alarm";
					reg = <0x2400>;
					interrupts = <0x02 0x24 0x00 0x03>;
					#thermal-sensor-cells = <0x00>;
					phandle = <0xa1>;
				};

				gpio@c000 {
					compatible = "qcom,pm660l-gpio", "qcom,spmi-gpio";
					reg = <0xc000>;
					gpio-controller;
					gpio-ranges = <0x3b 0x00 0x00 0x0c>;
					#gpio-cells = <0x02>;
					interrupt-controller;
					#interrupt-cells = <0x02>;
					phandle = <0x3b>;

					lcd-pwr-en-default-state {
						pins = "gpio5";
						function = "normal";
						bias-disable;
						phandle = <0xa2>;
					};

					vol-up-default-state {
						pins = "gpio7";
						function = "normal";
						bias-pull-up;
						input-enable;
						qcom,drive-strength = <0x00>;
						phandle = <0xa3>;
					};
				};
			};

			pmic@3 {
				compatible = "qcom,pm660l", "qcom,spmi-pmic";
				reg = <0x03 0x00>;
				#address-cells = <0x01>;
				#size-cells = <0x00>;

				pwm {
					compatible = "qcom,pm660l-lpg";
					status = "okay";
					qcom,power-source = <0x01>;
					#address-cells = <0x01>;
					#size-cells = <0x00>;

					led@3 {
						reg = <0x03>;
						color = <0x00>;
						function = "status";
					};
				};

				led-controller@d300 {
					compatible = "qcom,pm660l-flash-led", "qcom,spmi-flash-led";
					reg = <0xd300>;
					status = "disabled";
				};

				leds@d800 {
					compatible = "qcom,pm660l-wled";
					reg = <0xd800 0xd900>;
					interrupts = <0x03 0xd8 0x01 0x01 0x03 0xd8 0x02 0x01>;
					interrupt-names = "ovp", "short";
					label = "backlight";
					status = "okay";
					qcom,switching-freq = <0x320>;
					qcom,current-limit-microamp = <0x4e20>;
					qcom,num-strings = <0x03>;
					qcom,cabc;
					phandle = <0x5d>;
				};

				audio-codec@f000 {
					compatible = "qcom,pm8916-wcd-analog-codec";
					reg = <0xf000>;
					interrupts = <0x03 0xf0 0x00 0x00 0x03 0xf0 0x01 0x00 0x03 0xf0 0x02 0x00 0x03 0xf0 0x03 0x00 0x03 0xf0 0x04 0x00 0x03 0xf0 0x05 0x00 0x03 0xf0 0x06 0x00 0x03 0xf0 0x07 0x00 0x03 0xf1 0x00 0x00 0x03 0xf1 0x01 0x00 0x03 0xf1 0x02 0x00 0x03 0xf1 0x03 0x00 0x03 0xf1 0x04 0x00 0x03 0xf1 0x05 0x00>;
					interrupt-names = "cdc_spk_cnp_int", "cdc_spk_clip_int", "cdc_spk_ocp_int", "mbhc_ins_rem_det1", "mbhc_but_rel_det", "mbhc_but_press_det", "mbhc_ins_rem_det", "mbhc_switch_int", "cdc_ear_ocp_int", "cdc_hphr_ocp_int", "cdc_hphl_ocp_det", "cdc_ear_cnp_int", "cdc_hphr_cnp_int", "cdc_hphl_cnp_int";
					qcom,hphl-jack-type-normally-open;
					qcom,gnd-jack-type-normally-open;
					qcom,mbhc-vthreshold-low = <0x4b 0x96 0xed 0x1b5 0x1b5>;
					qcom,mbhc-vthreshold-high = <0x4b 0x96 0xed 0x1b5 0x1b5>;
					qcom,micbias2-ext-cap;
					#sound-dai-cells = <0x01>;
					status = "okay";
					vdd-micbias-supply = <0x3c>;
					qcom,micbias-lvl = <0xa28>;
					qcom,micbias1-ext-cap;
					phandle = <0x9b>;
				};

				regulators {
					compatible = "qcom,pm660l-regulators";
				};
			};
		};

		usb@a8f8800 {
			compatible = "qcom,sdm660-dwc3", "qcom,dwc3";
			reg = <0xa8f8800 0x400>;
			status = "okay";
			#address-cells = <0x01>;
			#size-cells = <0x01>;
			ranges;
			clocks = <0x27 0x31 0x27 0x5b 0x27 0x15 0x27 0x5d 0x27 0x5c>;
			clock-names = "cfg_noc", "core", "iface", "sleep", "mock_utmi";
			assigned-clocks = <0x27 0x5c 0x27 0x5b>;
			assigned-clock-rates = <0x124f800 0x7270e00>;
			interrupts = <0x00 0xb4 0x04 0x00 0x15b 0x04 0x00 0x85 0x04 0x00 0xf3 0x04>;
			interrupt-names = "pwr_event", "qusb2_phy", "hs_phy_irq", "ss_phy_irq";
			power-domains = <0x27 0x02>;
			resets = <0x27 0x07>;
			qcom,select-utmi-as-pipe-clk;

			usb@a800000 {
				compatible = "snps,dwc3";
				reg = <0xa800000 0xc8d0>;
				interrupts = <0x00 0x83 0x04>;
				snps,dis_u2_susphy_quirk;
				snps,dis_enblslpm_quirk;
				snps,parkmode-disable-ss-quirk;
				snps,dis-u1-entry-quirk;
				snps,dis-u2-entry-quirk;
				phys = <0x3d>;
				phy-names = "usb2-phy";
				snps,hird-threshold = [00];
				maximum-speed = "high-speed";
				dr_mode = "peripheral";
				status = "okay";
			};
		};

		phy@c010000 {
			compatible = "qcom,sdm660-qmp-usb3-phy";
			reg = <0xc010000 0x1000>;
			clocks = <0x27 0x5f 0x27 0x5e 0x27 0x61 0x27 0x60>;
			clock-names = "aux", "ref", "cfg_ahb", "pipe";
			clock-output-names = "usb3_phy_pipe_clk_src";
			#clock-cells = <0x00>;
			#phy-cells = <0x00>;
			resets = <0x27 0x04 0x27 0x05>;
			reset-names = "phy", "phy_phy";
			qcom,tcsr-reg = <0x2c 0x6b244>;
			status = "disabled";
		};

		phy@c012000 {
			compatible = "qcom,sdm660-qusb2-phy";
			reg = <0xc012000 0x180>;
			#phy-cells = <0x00>;
			clocks = <0x27 0x61 0x27 0x81>;
			clock-names = "cfg_ahb", "ref";
			resets = <0x27 0x00>;
			nvmem-cells = <0x3e>;
			status = "okay";
			vdd-supply = <0x3f>;
			vdda-pll-supply = <0x40>;
			vdda-phy-dpdm-supply = <0x3c>;
			phandle = <0x3d>;
		};

		phy@c014000 {
			compatible = "qcom,sdm660-qusb2-phy";
			reg = <0xc014000 0x180>;
			#phy-cells = <0x00>;
			clocks = <0x27 0x61 0x27 0x82>;
			clock-names = "cfg_ahb", "ref";
			resets = <0x27 0x01>;
			nvmem-cells = <0x3e>;
			status = "disabled";
			phandle = <0x4f>;
		};

		mmc@c084000 {
			compatible = "qcom,sdm630-sdhci", "qcom,sdhci-msm-v5";
			reg = <0xc084000 0x1000>;
			reg-names = "hc";
			interrupts = <0x00 0x7d 0x04 0x00 0xdd 0x04>;
			interrupt-names = "hc_irq", "pwr_irq";
			bus-width = <0x04>;
			clocks = <0x27 0x4d 0x27 0x4e 0x25>;
			clock-names = "iface", "core", "xo";
			resets = <0x27 0x0b>;
			interconnects = <0x41 0x03 0x41 0x0a 0x42 0x00 0x43 0x1c>;
			interconnect-names = "sdhc-ddr", "cpu-sdhc";
			operating-points-v2 = <0x44>;
			pinctrl-names = "default", "sleep";
			pinctrl-0 = <0x45>;
			pinctrl-1 = <0x46>;
			power-domains = <0x03 0x00>;
			status = "okay";
			cd-gpios = <0x29 0x36 0x00>;
			vmmc-supply = <0x47>;
			vqmmc-supply = <0x48>;

			opp-table {
				compatible = "operating-points-v2";
				phandle = <0x44>;

				opp-50000000 {
					opp-hz = <0x00 0x2faf080>;
					required-opps = <0x49>;
					opp-peak-kBps = <0x30d40 0x222e0>;
					opp-avg-kBps = <0x1fe9e 0x208c8>;
				};

				opp-100000000 {
					opp-hz = <0x00 0x5f5e100>;
					required-opps = <0x18>;
					opp-peak-kBps = <0x3d090 0x27100>;
					opp-avg-kBps = <0x2fdee 0x249f0>;
				};

				opp-200000000 {
					opp-hz = <0x00 0xbebc200>;
					required-opps = <0x1a>;
					opp-peak-kBps = <0x3e8000 0x3e8000>;
					opp-avg-kBps = <0x146cc2 0x146cc2>;
				};
			};
		};

		mmc@c0c4000 {
			compatible = "qcom,sdm630-sdhci", "qcom,sdhci-msm-v5";
			reg = <0xc0c4000 0x1000 0xc0c5000 0x1000 0xc0c8000 0x8000>;
			reg-names = "hc", "cqhci", "ice";
			interrupts = <0x00 0x6e 0x04 0x00 0x70 0x04>;
			interrupt-names = "hc_irq", "pwr_irq";
			clocks = <0x27 0x4a 0x27 0x4b 0x25 0x27 0x4c>;
			clock-names = "iface", "core", "xo", "ice";
			resets = <0x27 0x0a>;
			interconnects = <0x41 0x02 0x41 0x0a 0x42 0x00 0x43 0x1b>;
			interconnect-names = "sdhc-ddr", "cpu-sdhc";
			operating-points-v2 = <0x4a>;
			pinctrl-names = "default", "sleep";
			pinctrl-0 = <0x4b>;
			pinctrl-1 = <0x4c>;
			power-domains = <0x03 0x00>;
			bus-width = <0x08>;
			non-removable;
			status = "okay";
			supports-cqe;
			mmc-hs200-1_8v;
			mmc-hs400-1_8v;
			mmc-hs400-enhanced-strobe;
			vmmc-supply = <0x4d>;
			vqmmc-supply = <0x4e>;

			opp-table {
				compatible = "operating-points-v2";
				phandle = <0x4a>;

				opp-50000000 {
					opp-hz = <0x00 0x2faf080>;
					required-opps = <0x49>;
					opp-peak-kBps = <0x30d40 0x222e0>;
					opp-avg-kBps = <0x1fe9e 0x208c8>;
				};

				opp-100000000 {
					opp-hz = <0x00 0x5f5e100>;
					required-opps = <0x18>;
					opp-peak-kBps = <0x3d090 0x27100>;
					opp-avg-kBps = <0x2fdee 0x249f0>;
				};

				opp-384000000 {
					opp-hz = <0x00 0x16e36000>;
					required-opps = <0x1a>;
					opp-peak-kBps = <0x3e8000 0x3e8000>;
					opp-avg-kBps = <0x146cc2 0x146cc2>;
				};
			};
		};

		usb@c2f8800 {
			compatible = "qcom,sdm660-dwc3", "qcom,dwc3";
			reg = <0xc2f8800 0x400>;
			status = "disabled";
			#address-cells = <0x01>;
			#size-cells = <0x01>;
			ranges;
			clocks = <0x27 0x30 0x27 0x58 0x27 0x5a 0x27 0x59>;
			clock-names = "cfg_noc", "core", "sleep", "mock_utmi";
			assigned-clocks = <0x27 0x59 0x27 0x58>;
			assigned-clock-rates = <0x124f800 0x3938700>;
			interrupts = <0x00 0x90 0x04 0x00 0x15c 0x04 0x00 0x8b 0x04>;
			interrupt-names = "pwr_event", "qusb2_phy", "hs_phy_irq";
			qcom,select-utmi-as-pipe-clk;
			resets = <0x27 0x06>;

			usb@c200000 {
				compatible = "snps,dwc3";
				reg = <0xc200000 0xc8d0>;
				interrupts = <0x00 0x8f 0x04>;
				snps,dis_u2_susphy_quirk;
				snps,dis_enblslpm_quirk;
				snps,dis-u1-entry-quirk;
				snps,dis-u2-entry-quirk;
				maximum-speed = "high-speed";
				phys = <0x4f>;
				phy-names = "usb2-phy";
				snps,hird-threshold = [00];
			};
		};

		clock-controller@c8c0000 {
			compatible = "qcom,mmcc-sdm660";
			reg = <0xc8c0000 0x40000>;
			#clock-cells = <0x01>;
			#reset-cells = <0x01>;
			#power-domain-cells = <0x01>;
			clock-names = "xo", "sleep_clk", "gpll0", "gpll0_div", "dsi0pll", "dsi0pllbyte", "dsi1pll", "dsi1pllbyte", "dp_link_2x_clk_divsel_five", "dp_vco_divided_clk_src_mux";
			clocks = <0x28 0x00 0x26 0x27 0x3c 0x27 0x3d 0x50 0x01 0x50 0x00 0x51 0x01 0x51 0x00 0x00 0x00>;
			phandle = <0x02>;
		};

		display-subsystem@c900000 {
			compatible = "qcom,mdss";
			reg = <0xc900000 0x1000 0xc9b0000 0x1040>;
			reg-names = "mdss_phys", "vbif_phys";
			power-domains = <0x02 0x02>;
			resets = <0x02 0x01>;
			clocks = <0x02 0x60 0x02 0x61 0x02 0x74 0x02 0x70>;
			clock-names = "iface", "bus", "vsync", "core";
			interrupts = <0x00 0x53 0x04>;
			interrupt-controller;
			#interrupt-cells = <0x01>;
			#address-cells = <0x01>;
			#size-cells = <0x01>;
			ranges;
			status = "okay";
			phandle = <0x52>;

			display-controller@c901000 {
				compatible = "qcom,sdm660-mdp5", "qcom,mdp5";
				reg = <0xc901000 0x89000>;
				reg-names = "mdp_phys";
				interrupt-parent = <0x52>;
				interrupts = <0x00>;
				assigned-clocks = <0x02 0x70 0x02 0x74>;
				assigned-clock-rates = <0x11e1a300 0x124f800>;
				clocks = <0x02 0x60 0x02 0x61 0x02 0x70 0x02 0x74>;
				clock-names = "iface", "bus", "core", "vsync";
				interconnects = <0x53 0x02 0x33 0x05 0x53 0x03 0x33 0x05 0x42 0x00 0x53 0x11>;
				interconnect-names = "mdp0-mem", "mdp1-mem", "rotator-mem";
				iommus = <0x54 0x00>;
				operating-points-v2 = <0x55>;
				power-domains = <0x03 0x00>;

				ports {
					#address-cells = <0x01>;
					#size-cells = <0x00>;

					port@0 {
						reg = <0x00>;

						endpoint {
							remote-endpoint = <0x56>;
							phandle = <0x5b>;
						};
					};

					port@1 {
						reg = <0x01>;

						endpoint {
							remote-endpoint = <0x57>;
							phandle = <0x62>;
						};
					};
				};

				opp-table {
					compatible = "operating-points-v2";
					phandle = <0x55>;

					opp-150000000 {
						opp-hz = <0x00 0x8f0d180>;
						opp-peak-kBps = <0x4e200 0x4e200 0x12c00>;
						required-opps = <0x49>;
					};

					opp-275000000 {
						opp-hz = <0x00 0x10642ac0>;
						opp-peak-kBps = <0x61a800 0x61a800 0x27100>;
						required-opps = <0x18>;
					};

					opp-300000000 {
						opp-hz = <0x00 0x11e1a300>;
						opp-peak-kBps = <0x61a800 0x61a800 0x2e630>;
						required-opps = <0x19>;
					};

					opp-330000000 {
						opp-hz = <0x00 0x13ab6680>;
						opp-peak-kBps = <0x61a800 0x61a800 0x3a980>;
						required-opps = <0x1a>;
					};

					opp-412500000 {
						opp-hz = <0x00 0x18964020>;
						opp-peak-kBps = <0x61a800 0x61a800 0x4e200>;
						required-opps = <0x58>;
					};
				};
			};

			dsi@c994000 {
				compatible = "qcom,sdm660-dsi-ctrl", "qcom,mdss-dsi-ctrl";
				reg = <0xc994000 0x400>;
				reg-names = "dsi_ctrl";
				operating-points-v2 = <0x59>;
				power-domains = <0x03 0x00>;
				interrupt-parent = <0x52>;
				interrupts = <0x04>;
				assigned-clocks = <0x02 0x01 0x02 0x83>;
				assigned-clock-parents = <0x50 0x00 0x50 0x01>;
				clocks = <0x02 0x70 0x02 0x62 0x02 0x63 0x02 0x77 0x02 0x60 0x02 0x61 0x02 0x75 0x02 0x71 0x02 0x6d>;
				clock-names = "mdp_core", "byte", "byte_intf", "mnoc", "iface", "bus", "core_mmss", "pixel", "core";
				phys = <0x50>;
				status = "okay";
				#address-cells = <0x01>;
				#size-cells = <0x00>;
				vdd-supply = <0x3f>;
				vdda-supply = <0x5a>;

				ports {
					#address-cells = <0x01>;
					#size-cells = <0x00>;

					port@0 {
						reg = <0x00>;

						endpoint {
							remote-endpoint = <0x5b>;
							phandle = <0x56>;
						};
					};

					port@1 {
						reg = <0x01>;

						endpoint {
							data-lanes = <0x00 0x01 0x02 0x03>;
							remote-endpoint = <0x5c>;
							phandle = <0x61>;
						};
					};
				};

				panel@0 {
					compatible = "boe,tv080wum-nx2", "novatek,nt51021";
					reg = <0x00>;
					backlight = <0x5d>;
					avdd-supply = <0x5e>;
					reset-gpios = <0x29 0x3e 0x01>;
					pinctrl-names = "default";
					pinctrl-0 = <0x5f 0x60>;

					port {

						endpoint {
							remote-endpoint = <0x61>;
							phandle = <0x5c>;
						};
					};
				};
			};

			phy@c994400 {
				compatible = "qcom,dsi-phy-14nm-660";
				reg = <0xc994400 0x100 0xc994500 0x300 0xc994800 0x188>;
				reg-names = "dsi_phy", "dsi_phy_lane", "dsi_pll";
				#clock-cells = <0x01>;
				#phy-cells = <0x00>;
				clocks = <0x02 0x60 0x25>;
				clock-names = "iface", "ref";
				status = "okay";
				vcca-supply = <0x3f>;
				phandle = <0x50>;
			};

			dsi@c996000 {
				compatible = "qcom,sdm660-dsi-ctrl", "qcom,mdss-dsi-ctrl";
				reg = <0xc996000 0x400>;
				reg-names = "dsi_ctrl";
				operating-points-v2 = <0x59>;
				power-domains = <0x03 0x00>;
				interrupt-parent = <0x52>;
				interrupts = <0x05>;
				assigned-clocks = <0x02 0x02 0x02 0x84>;
				assigned-clock-parents = <0x51 0x00 0x51 0x01>;
				clocks = <0x02 0x70 0x02 0x65 0x02 0x66 0x02 0x77 0x02 0x60 0x02 0x61 0x02 0x75 0x02 0x72 0x02 0x6e>;
				clock-names = "mdp_core", "byte", "byte_intf", "mnoc", "iface", "bus", "core_mmss", "pixel", "core";
				phys = <0x51>;
				status = "disabled";

				ports {
					#address-cells = <0x01>;
					#size-cells = <0x00>;

					port@0 {
						reg = <0x00>;

						endpoint {
							remote-endpoint = <0x62>;
							phandle = <0x57>;
						};
					};

					port@1 {
						reg = <0x01>;

						endpoint {
						};
					};
				};
			};

			phy@c996400 {
				compatible = "qcom,dsi-phy-14nm-660";
				reg = <0xc996400 0x100 0xc996500 0x300 0xc996800 0x188>;
				reg-names = "dsi_phy", "dsi_phy_lane", "dsi_pll";
				#clock-cells = <0x01>;
				#phy-cells = <0x00>;
				clocks = <0x02 0x60 0x28 0x00>;
				clock-names = "iface", "ref";
				status = "disabled";
				phandle = <0x51>;
			};
		};

		dma-controller@c144000 {
			compatible = "qcom,bam-v1.7.0";
			reg = <0xc144000 0x1f000>;
			interrupts = <0x00 0xee 0x04>;
			clocks = <0x27 0x19>;
			clock-names = "bam_clk";
			#dma-cells = <0x01>;
			qcom,ee = <0x00>;
			qcom,controlled-remotely;
			num-channels = <0x12>;
			qcom,num-ees = <0x04>;
			phandle = <0x63>;
		};

		serial@c16f000 {
			compatible = "qcom,msm-uartdm-v1.4", "qcom,msm-uartdm";
			reg = <0xc16f000 0x200>;
			interrupts = <0x00 0x6b 0x04>;
			clocks = <0x27 0x22 0x27 0x19>;
			clock-names = "core", "iface";
			dmas = <0x63 0x00 0x63 0x01>;
			dma-names = "tx", "rx";
			pinctrl-names = "default", "sleep";
			pinctrl-0 = <0x64>;
			pinctrl-1 = <0x65>;
			status = "disabled";
		};

		serial@c170000 {
			compatible = "qcom,msm-uartdm-v1.4", "qcom,msm-uartdm";
			reg = <0xc170000 0x1000>;
			interrupts = <0x00 0x6c 0x04>;
			clocks = <0x27 0x23 0x27 0x19>;
			clock-names = "core", "iface";
			dmas = <0x63 0x02 0x63 0x03>;
			dma-names = "tx", "rx";
			pinctrl-names = "default";
			pinctrl-0 = <0x66>;
			status = "disabled";
		};

		i2c@c175000 {
			compatible = "qcom,i2c-qup-v2.2.1";
			reg = <0xc175000 0x600>;
			interrupts = <0x00 0x5f 0x04>;
			clocks = <0x27 0x1a 0x27 0x19>;
			clock-names = "core", "iface";
			clock-frequency = <0x61a80>;
			dmas = <0x63 0x04 0x63 0x05>;
			dma-names = "tx", "rx";
			pinctrl-names = "default", "sleep";
			pinctrl-0 = <0x67>;
			pinctrl-1 = <0x68>;
			#address-cells = <0x01>;
			#size-cells = <0x00>;
			status = "disabled";
		};

		i2c@c176000 {
			compatible = "qcom,i2c-qup-v2.2.1";
			reg = <0xc176000 0x600>;
			interrupts = <0x00 0x60 0x04>;
			clocks = <0x27 0x1c 0x27 0x19>;
			clock-names = "core", "iface";
			clock-frequency = <0x61a80>;
			dmas = <0x63 0x06 0x63 0x07>;
			dma-names = "tx", "rx";
			pinctrl-names = "default", "sleep";
			pinctrl-0 = <0x69>;
			pinctrl-1 = <0x6a>;
			#address-cells = <0x01>;
			#size-cells = <0x00>;
			status = "disabled";
		};

		i2c@c177000 {
			compatible = "qcom,i2c-qup-v2.2.1";
			reg = <0xc177000 0x600>;
			interrupts = <0x00 0x61 0x04>;
			clocks = <0x27 0x1e 0x27 0x19>;
			clock-names = "core", "iface";
			clock-frequency = <0x61a80>;
			dmas = <0x63 0x08 0x63 0x09>;
			dma-names = "tx", "rx";
			pinctrl-names = "default", "sleep";
			pinctrl-0 = <0x6b>;
			pinctrl-1 = <0x6c>;
			#address-cells = <0x01>;
			#size-cells = <0x00>;
			status = "okay";

			touchscreen@38 {
				compatible = "edt,edt-ft5406";
				reg = <0x38>;
				vcc-supply = <0x6d>;
				pinctrl-0 = <0x6e 0x6f>;
				pinctrl-names = "default";
				interrupts-extended = <0x29 0x43 0x02>;
				reset-gpios = <0x29 0x42 0x01>;
				touchscreen-size-x = <0x4b0>;
				touchscreen-size-y = <0x780>;
			};
		};

		i2c@c178000 {
			compatible = "qcom,i2c-qup-v2.2.1";
			reg = <0xc178000 0x600>;
			interrupts = <0x00 0x62 0x04>;
			clocks = <0x27 0x20 0x27 0x19>;
			clock-names = "core", "iface";
			clock-frequency = <0x61a80>;
			dmas = <0x63 0x0a 0x63 0x0b>;
			dma-names = "tx", "rx";
			pinctrl-names = "default", "sleep";
			pinctrl-0 = <0x70>;
			pinctrl-1 = <0x71>;
			#address-cells = <0x01>;
			#size-cells = <0x00>;
			status = "disabled";
		};

		dma-controller@c184000 {
			compatible = "qcom,bam-v1.7.0";
			reg = <0xc184000 0x1f000>;
			interrupts = <0x00 0xef 0x04>;
			clocks = <0x27 0x24>;
			clock-names = "bam_clk";
			#dma-cells = <0x01>;
			qcom,ee = <0x00>;
			qcom,controlled-remotely;
			num-channels = <0x12>;
			qcom,num-ees = <0x04>;
			phandle = <0x72>;
		};

		serial@c1af000 {
			compatible = "qcom,msm-uartdm-v1.4", "qcom,msm-uartdm";
			reg = <0xc1af000 0x200>;
			interrupts = <0x00 0x71 0x04>;
			clocks = <0x27 0x2d 0x27 0x24>;
			clock-names = "core", "iface";
			dmas = <0x72 0x00 0x72 0x01>;
			dma-names = "tx", "rx";
			pinctrl-names = "default", "sleep";
			pinctrl-0 = <0x73>;
			pinctrl-1 = <0x74>;
			status = "okay";

			bluetooth {
				compatible = "qcom,wcn3990-bt";
				vddxo-supply = <0x75>;
				vddrf-supply = <0x76>;
				vddch0-supply = <0x77>;
				vddio-supply = <0x78>;
				max-speed = <0x30d400>;
			};
		};

		i2c@c1b5000 {
			compatible = "qcom,i2c-qup-v2.2.1";
			reg = <0xc1b5000 0x600>;
			interrupts = <0x00 0x65 0x04>;
			clocks = <0x27 0x25 0x27 0x24>;
			clock-names = "core", "iface";
			clock-frequency = <0x61a80>;
			dmas = <0x72 0x04 0x72 0x05>;
			dma-names = "tx", "rx";
			pinctrl-names = "default", "sleep";
			pinctrl-0 = <0x79>;
			pinctrl-1 = <0x7a>;
			#address-cells = <0x01>;
			#size-cells = <0x00>;
			status = "disabled";
		};

		i2c@c1b6000 {
			compatible = "qcom,i2c-qup-v2.2.1";
			reg = <0xc1b6000 0x600>;
			interrupts = <0x00 0x66 0x04>;
			clocks = <0x27 0x27 0x27 0x24>;
			clock-names = "core", "iface";
			clock-frequency = <0x61a80>;
			dmas = <0x72 0x06 0x72 0x07>;
			dma-names = "tx", "rx";
			pinctrl-names = "default", "sleep";
			pinctrl-0 = <0x7b>;
			pinctrl-1 = <0x7c>;
			#address-cells = <0x01>;
			#size-cells = <0x00>;
			status = "disabled";
		};

		i2c@c1b7000 {
			compatible = "qcom,i2c-qup-v2.2.1";
			reg = <0xc1b7000 0x600>;
			interrupts = <0x00 0x67 0x04>;
			clocks = <0x27 0x29 0x27 0x24>;
			clock-names = "core", "iface";
			clock-frequency = <0x61a80>;
			dmas = <0x72 0x08 0x72 0x09>;
			dma-names = "tx", "rx";
			pinctrl-names = "default", "sleep";
			pinctrl-0 = <0x7d>;
			pinctrl-1 = <0x7e>;
			#address-cells = <0x01>;
			#size-cells = <0x00>;
			status = "disabled";
		};

		spi@c1b7000 {
			compatible = "qcom,spi-qup-v2.2.1";
			reg = <0xc1b7000 0x600>;
			interrupts = <0x00 0x67 0x04>;
			clocks = <0x27 0x2a 0x27 0x24>;
			clock-names = "core", "iface";
			dmas = <0x72 0x08 0x72 0x09>;
			dma-names = "tx", "rx";
			pinctrl-names = "default", "sleep";
			pinctrl-0 = <0x7f>;
			pinctrl-1 = <0x80>;
			#address-cells = <0x01>;
			#size-cells = <0x00>;
			status = "disabled";
		};

		i2c@c1b8000 {
			compatible = "qcom,i2c-qup-v2.2.1";
			reg = <0xc1b8000 0x600>;
			interrupts = <0x00 0x68 0x04>;
			clocks = <0x27 0x2b 0x27 0x24>;
			clock-names = "core", "iface";
			clock-frequency = <0x61a80>;
			dmas = <0x72 0x0a 0x72 0x0b>;
			dma-names = "tx", "rx";
			pinctrl-names = "default", "sleep";
			pinctrl-0 = <0x81>;
			pinctrl-1 = <0x82>;
			#address-cells = <0x01>;
			#size-cells = <0x00>;
			status = "disabled";
		};

		sram@146bf000 {
			compatible = "qcom,sdm630-imem", "syscon", "simple-mfd";
			reg = <0x146bf000 0x1000>;
			#address-cells = <0x01>;
			#size-cells = <0x01>;
			ranges = <0x00 0x146bf000 0x1000>;

			pil-reloc@94c {
				compatible = "qcom,pil-reloc-info";
				reg = <0x94c 0xc8>;
			};
		};

		ipa@14780000 {
			compatible = "qcom,sdm660-ipa", "qcom,ipa-lite-v2.6";
			reg = <0x14780000 0x4f000>;
			clocks = <0x28 0x44>;
			interrupts = <0x00 0x14d 0x04 0x00 0x1b0 0x04>;
			interrupt-names = "ipa", "dma";
			interconnects = <0x41 0x00 0x33 0x05 0x42 0x00 0x83 0x0a>;
			interconnect-names = "ipa-mem", "cpu-cfg";
			iommus = <0x84 0x19c0 0x84 0x19c2>;
			modem-remoteproc = <0x85>;
			status = "okay";
		};

		camss@ca00020 {
			compatible = "qcom,sdm660-camss";
			reg = <0xca00020 0x10 0xca30000 0x100 0xca30400 0x100 0xca30800 0x100 0xca30c00 0x100 0xc824000 0x1000 0xca00120 0x04 0xc825000 0x1000 0xca00124 0x04 0xc826000 0x1000 0xca00128 0x04 0xca31000 0x500 0xca10000 0x1000 0xca14000 0x1000>;
			reg-names = "csi_clk_mux", "csid0", "csid1", "csid2", "csid3", "csiphy0", "csiphy0_clk_mux", "csiphy1", "csiphy1_clk_mux", "csiphy2", "csiphy2_clk_mux", "ispif", "vfe0", "vfe1";
			interrupts = <0x00 0x128 0x01 0x00 0x129 0x01 0x00 0x12a 0x01 0x00 0x12b 0x01 0x00 0x4e 0x01 0x00 0x4f 0x01 0x00 0x50 0x01 0x00 0x135 0x01 0x00 0x13a 0x01 0x00 0x13b 0x01>;
			interrupt-names = "csid0", "csid1", "csid2", "csid3", "csiphy0", "csiphy1", "csiphy2", "ispif", "vfe0", "vfe1";
			clocks = <0x02 0x27 0x02 0x2a 0x02 0x2b 0x02 0x2c 0x02 0x2d 0x02 0x32 0x02 0x33 0x02 0x2a 0x02 0x35 0x02 0x36 0x02 0x37 0x02 0x38 0x02 0x2b 0x02 0x3a 0x02 0x3b 0x02 0x3c 0x02 0x3d 0x02 0x2c 0x02 0x3f 0x02 0x40 0x02 0x41 0x02 0x42 0x02 0x2d 0x02 0x43 0x02 0x44 0x02 0x34 0x02 0x39 0x02 0x3e 0x02 0x5e 0x02 0x45 0x02 0x46 0x02 0x4c 0x02 0x7a 0x02 0x55 0x02 0x56 0x02 0x57 0x02 0x58 0x02 0x59 0x02 0x5a 0x02 0x5b 0x02 0x5c 0x02 0x5d>;
			clock-names = "ahb", "cphy_csid0", "cphy_csid1", "cphy_csid2", "cphy_csid3", "csi0_ahb", "csi0", "csi0_phy", "csi0_pix", "csi0_rdi", "csi1_ahb", "csi1", "csi1_phy", "csi1_pix", "csi1_rdi", "csi2_ahb", "csi2", "csi2_phy", "csi2_pix", "csi2_rdi", "csi3_ahb", "csi3", "csi3_phy", "csi3_pix", "csi3_rdi", "csiphy0_timer", "csiphy1_timer", "csiphy2_timer", "csiphy_ahb2crif", "csi_vfe0", "csi_vfe1", "ispif_ahb", "throttle_axi", "top_ahb", "vfe0_ahb", "vfe0", "vfe0_stream", "vfe1_ahb", "vfe1", "vfe1_stream", "vfe_ahb", "vfe_axi";
			interconnects = <0x53 0x05 0x33 0x05>;
			interconnect-names = "vfe-mem";
			iommus = <0x54 0xc00 0x54 0xc01 0x54 0xc02 0x54 0xc03>;
			power-domains = <0x02 0x04 0x02 0x05>;
			status = "disabled";

			ports {
				#address-cells = <0x01>;
				#size-cells = <0x00>;
			};
		};

		cci@ca0c000 {
			compatible = "qcom,msm8996-cci";
			#address-cells = <0x01>;
			#size-cells = <0x00>;
			reg = <0xca0c000 0x1000>;
			interrupts = <0x00 0x127 0x01>;
			assigned-clocks = <0x02 0x28 0x02 0x29>;
			assigned-clock-rates = <0x4d0e900 0x23c3460>;
			clocks = <0x02 0x55 0x02 0x28 0x02 0x29 0x02 0x27>;
			clock-names = "camss_top_ahb", "cci_ahb", "cci", "camss_ahb";
			pinctrl-names = "default";
			pinctrl-0 = <0x86 0x87>;
			power-domains = <0x02 0x03>;
			status = "disabled";

			i2c-bus@0 {
				reg = <0x00>;
				clock-frequency = <0x61a80>;
				#address-cells = <0x01>;
				#size-cells = <0x00>;
			};

			i2c-bus@1 {
				reg = <0x01>;
				clock-frequency = <0x61a80>;
				#address-cells = <0x01>;
				#size-cells = <0x00>;
			};
		};

		video-codec@cc00000 {
			compatible = "qcom,sdm660-venus";
			reg = <0xcc00000 0xff000>;
			clocks = <0x02 0x81 0x02 0x7f 0x02 0x80 0x02 0x7e>;
			clock-names = "core", "iface", "bus", "bus_throttle";
			interconnects = <0x42 0x00 0x53 0x0d 0x53 0x04 0x33 0x05>;
			interconnect-names = "cpu-cfg", "video-mem";
			interrupts = <0x00 0x11f 0x04>;
			iommus = <0x54 0x400 0x54 0x401 0x54 0x40a 0x54 0x407 0x54 0x40e 0x54 0x40f 0x54 0x408 0x54 0x409 0x54 0x40b 0x54 0x40c 0x54 0x40d 0x54 0x410 0x54 0x421 0x54 0x428 0x54 0x429 0x54 0x42b 0x54 0x42c 0x54 0x42d 0x54 0x411 0x54 0x431>;
			memory-region = <0x88>;
			power-domains = <0x02 0x00>;
			status = "okay";
			firmware-name = "qcom/venus-4.4/venus.mdt";

			video-decoder {
				compatible = "venus-decoder";
				clocks = <0x02 0x82>;
				clock-names = "vcodec0_core";
				power-domains = <0x02 0x01>;
			};

			video-encoder {
				compatible = "venus-encoder";
				clocks = <0x02 0x82>;
				clock-names = "vcodec0_core";
				power-domains = <0x02 0x01>;
			};
		};

		iommu@cd00000 {
			compatible = "qcom,sdm630-smmu-v2", "qcom,smmu-v2";
			reg = <0xcd00000 0x40000>;
			clocks = <0x02 0x77 0x02 0x25 0x02 0x26>;
			clock-names = "iface-mm", "iface-smmu", "bus-smmu";
			#global-interrupts = <0x02>;
			#iommu-cells = <0x01>;
			interrupts = <0x00 0xe5 0x04 0x00 0xe7 0x04 0x00 0x107 0x04 0x00 0x10a 0x04 0x00 0x10b 0x04 0x00 0x10c 0x04 0x00 0xf4 0x04 0x00 0xf5 0x04 0x00 0xf7 0x04 0x00 0xf8 0x04 0x00 0xf9 0x04 0x00 0xfa 0x04 0x00 0xfb 0x04 0x00 0xfc 0x04 0x00 0xfd 0x04 0x00 0xfe 0x04 0x00 0xff 0x04 0x00 0x100 0x04 0x00 0x104 0x04 0x00 0x105 0x04 0x00 0x106 0x04 0x00 0x110 0x04 0x00 0x111 0x04 0x00 0x112 0x04 0x00 0x113 0x04 0x00 0x114 0x04>;
			status = "okay";
			phandle = <0x54>;
		};

		pinctrl@15070000 {
			compatible = "qcom,sdm660-lpass-lpi-pinctrl";
			reg = <0x15070000 0x20000>;
			gpio-controller;
			#gpio-cells = <0x02>;
			gpio-ranges = <0x89 0x00 0x00 0x20>;
			phandle = <0x89>;

			cdc-pdm-default-state {
				phandle = <0x96>;

				clk-pins {
					pins = "gpio18";
					function = "pdm_clk";
					drive-strength = <0x08>;
					output-high;
				};

				sync-pins {
					pins = "gpio19";
					function = "pdm_sync";
					drive-strength = <0x04>;
					output-high;
				};

				tx-pins {
					pins = "gpio20";
					function = "pdm_tx";
					drive-strength = <0x08>;
				};

				rx-pins {
					pins = "gpio21", "gpio23", "gpio25";
					function = "pdm_rx";
					drive-strength = <0x04>;
					output-high;
				};
			};

			cdc-comp-default-state {
				pins = "gpio22", "gpio24";
				function = "comp_rx";
				drive-strength = <0x08>;
			};

			cdc-dmic-default-state {
				phandle = <0x97>;

				dmic1-clk-pins {
					pins = "gpio26";
					function = "dmic1_clk";
					drive-strength = <0x08>;
					output-high;
				};

				dmic1-data-pins {
					pins = "gpio27";
					function = "dmic1_data";
					drive-strength = <0x08>;
					output-high;
				};

				dmic2-clk-pins {
					pins = "gpio28";
					function = "dmic2_clk";
					drive-strength = <0x08>;
					input-enable;
				};

				dmic2-data-pins {
					pins = "gpio29";
					function = "dmic2_data";
					drive-strength = <0x08>;
					input-enable;
				};
			};
		};

		audio-codec@152c0000 {
			compatible = "qcom,msm8916-wcd-digital-codec";
			reg = <0x152c0000 0x400>;
			clocks = <0x8a 0x8b 0x33 0x01>;
			clock-names = "ahbix-clk", "mclk";
			assigned-clocks = <0x8b 0x33 0x01>;
			assigned-clock-rates = <0x927c00>;
			sound-name-prefix = "Digital";
			#sound-dai-cells = <0x01>;
			status = "okay";
			phandle = <0x9c>;
		};

		remoteproc@15700000 {
			compatible = "qcom,sdm660-adsp-pas";
			reg = <0x15700000 0x4040>;
			interrupts-extended = <0x01 0x00 0xa2 0x01 0x8c 0x00 0x01 0x8c 0x01 0x01 0x8c 0x02 0x01 0x8c 0x03 0x01>;
			interrupt-names = "wdog", "fatal", "ready", "handover", "stop-ack";
			clocks = <0x28 0x00>;
			clock-names = "xo";
			memory-region = <0x8d>;
			power-domains = <0x03 0x00>;
			power-domain-names = "cx";
			qcom,smem-states = <0x8e 0x00>;
			qcom,smem-state-names = "stop";

			glink-edge {
				interrupts = <0x00 0x9d 0x01>;
				label = "lpass";
				mboxes = <0x1c 0x09>;
				qcom,remote-pid = <0x02>;

				apr {
					compatible = "qcom,apr-v2";
					qcom,glink-channels = "apr_audio_svc";
					qcom,domain = <0x04>;
					#address-cells = <0x01>;
					#size-cells = <0x00>;

					service@3 {
						reg = <0x03>;
						compatible = "qcom,q6core";
					};

					service@4 {
						compatible = "qcom,q6afe";
						reg = <0x04>;
						qcom,protection-domain = "avs/audio", "msm/adsp/audio_pd";

						clock-controller {
							compatible = "qcom,q6afe-clocks";
							#clock-cells = <0x02>;
							phandle = <0x8b>;
						};

						dais {
							compatible = "qcom,q6afe-dais";
							#address-cells = <0x01>;
							#size-cells = <0x00>;
							#sound-dai-cells = <0x01>;
							phandle = <0x99>;

							dai@81 {
								reg = <0x89>;
								qcom,sd-lines = <0x00 0x01>;
							};

							dai@88 {
								reg = <0x90>;
								qcom,sd-lines = <0x00 0x01>;
							};
						};
					};

					service@7 {
						compatible = "qcom,q6asm";
						reg = <0x07>;
						qcom,protection-domain = "avs/audio", "msm/adsp/audio_pd";

						dais {
							compatible = "qcom,q6asm-dais";
							#address-cells = <0x01>;
							#size-cells = <0x00>;
							#sound-dai-cells = <0x01>;
							iommus = <0x8f 0x01>;
							phandle = <0x98>;

							dai@0 {
								reg = <0x00>;
							};

							dai@1 {
								reg = <0x01>;
							};
						};
					};

					service@8 {
						compatible = "qcom,q6adm";
						reg = <0x08>;
						qcom,protection-domain = "avs/audio", "msm/adsp/audio_pd";

						routing {
							compatible = "qcom,q6adm-routing";
							#sound-dai-cells = <0x00>;
							phandle = <0x9a>;
						};
					};
				};

				fastrpc {
					compatible = "qcom,fastrpc";
					qcom,glink-channels = "fastrpcglink-apps-dsp";
					label = "adsp";
					qcom,non-secure-domain;
					#address-cells = <0x01>;
					#size-cells = <0x00>;

					compute-cb@1 {
						compatible = "qcom,fastrpc-compute-cb";
						reg = <0x01>;
						iommus = <0x8f 0x03>;
					};

					compute-cb@2 {
						compatible = "qcom,fastrpc-compute-cb";
						reg = <0x02>;
						iommus = <0x8f 0x07>;
					};

					compute-cb@3 {
						compatible = "qcom,fastrpc-compute-cb";
						reg = <0x03>;
						iommus = <0x8f 0x08>;
					};

					compute-cb@4 {
						compatible = "qcom,fastrpc-compute-cb";
						reg = <0x04>;
						iommus = <0x8f 0x09>;
					};
				};
			};
		};

		interconnect@17900000 {
			compatible = "qcom,sdm660-gnoc";
			reg = <0x17900000 0xe000>;
			#interconnect-cells = <0x01>;
			phandle = <0x42>;
		};

		mailbox@17911000 {
			compatible = "qcom,sdm660-apcs-hmss-global", "qcom,msm8994-apcs-kpss-global";
			reg = <0x17911000 0x1000>;
			#mbox-cells = <0x01>;
			phandle = <0x1c>;
		};

		timer@17920000 {
			#address-cells = <0x01>;
			#size-cells = <0x01>;
			ranges;
			compatible = "arm,armv7-timer-mem";
			reg = <0x17920000 0x1000>;
			clock-frequency = <0x124f800>;

			frame@17921000 {
				frame-number = <0x00>;
				interrupts = <0x00 0x08 0x04 0x00 0x07 0x04>;
				reg = <0x17921000 0x1000 0x17922000 0x1000>;
			};

			frame@17923000 {
				frame-number = <0x01>;
				interrupts = <0x00 0x09 0x04>;
				reg = <0x17923000 0x1000>;
				status = "disabled";
			};

			frame@17924000 {
				frame-number = <0x02>;
				interrupts = <0x00 0x0a 0x04>;
				reg = <0x17924000 0x1000>;
				status = "disabled";
			};

			frame@17925000 {
				frame-number = <0x03>;
				interrupts = <0x00 0x0b 0x04>;
				reg = <0x17925000 0x1000>;
				status = "disabled";
			};

			frame@17926000 {
				frame-number = <0x04>;
				interrupts = <0x00 0x0c 0x04>;
				reg = <0x17926000 0x1000>;
				status = "disabled";
			};

			frame@17927000 {
				frame-number = <0x05>;
				interrupts = <0x00 0x0d 0x04>;
				reg = <0x17927000 0x1000>;
				status = "disabled";
			};

			frame@17928000 {
				frame-number = <0x06>;
				interrupts = <0x00 0x0e 0x04>;
				reg = <0x17928000 0x1000>;
				status = "disabled";
			};
		};

		interrupt-controller@17a00000 {
			compatible = "arm,gic-v3";
			reg = <0x17a00000 0x10000 0x17b00000 0x100000>;
			#interrupt-cells = <0x03>;
			#address-cells = <0x01>;
			#size-cells = <0x01>;
			ranges;
			interrupt-controller;
			#redistributor-regions = <0x01>;
			redistributor-stride = <0x00 0x20000>;
			interrupts = <0x01 0x09 0x04>;
			phandle = <0x01>;
		};

		wifi@18800000 {
			compatible = "qcom,wcn3990-wifi";
			reg = <0x18800000 0x800000>;
			reg-names = "membase";
			memory-region = <0x90>;
			clocks = <0x28 0x16>;
			clock-names = "cxo_ref_clk_pin";
			interrupts = <0x00 0x19d 0x04 0x00 0x19e 0x04 0x00 0x19f 0x04 0x00 0x1a0 0x04 0x00 0x1a1 0x04 0x00 0x1a2 0x04 0x00 0x1a4 0x04 0x00 0x1a5 0x04 0x00 0x1a6 0x04 0x00 0x1a7 0x04 0x00 0x1a8 0x04 0x00 0x1a9 0x04>;
			iommus = <0x84 0x1a00 0x84 0x1a01>;
			qcom,snoc-host-cap-8bit-quirk;
			qcom,no-msa-ready-indicator;
			status = "okay";
			vdd-0.8-cx-mx-supply = <0x91>;
			vdd-1.8-xo-supply = <0x75>;
			vdd-1.3-rfa-supply = <0x76>;
			vdd-3.3-ch0-supply = <0x77>;
		};

		iommu@5180000 {
			compatible = "qcom,sdm630-smmu-v2", "qcom,smmu-v2";
			reg = <0x5180000 0x40000>;
			#iommu-cells = <0x01>;
			clocks = <0x27 0x84>;
			clock-names = "bus";
			power-domains = <0x27 0x03>;
			#global-interrupts = <0x02>;
			interrupts = <0x00 0xe5 0x04 0x00 0xe7 0x04 0x00 0x215 0x04 0x00 0x216 0x04 0x00 0x217 0x04 0x00 0x218 0x04 0x00 0x219 0x04 0x00 0x21a 0x04 0x00 0x21b 0x04 0x00 0x21c 0x04 0x00 0x21d 0x04 0x00 0x21e 0x04 0x00 0x21f 0x04 0x00 0x220 0x04 0x00 0x221 0x04 0x00 0x222 0x04 0x00 0x223 0x04 0x00 0x224 0x04 0x00 0x225 0x04>;
			phandle = <0x95>;
		};

		remoteproc@1a300000 {
			compatible = "qcom,sdm660-cdsp-pas";
			reg = <0x1a300000 0x100>;
			interrupts-extended = <0x01 0x00 0x206 0x01 0x92 0x00 0x01 0x92 0x01 0x01 0x92 0x02 0x01 0x92 0x03 0x01>;
			interrupt-names = "wdog", "fatal", "ready", "handover", "stop-ack";
			clocks = <0x28 0x00>;
			clock-names = "xo";
			memory-region = <0x93>;
			power-domains = <0x03 0x00>;
			power-domain-names = "cx";
			qcom,smem-states = <0x94 0x00>;
			qcom,smem-state-names = "stop";

			glink-edge {
				interrupts = <0x00 0x201 0x01>;
				label = "turing";
				mboxes = <0x1c 0x1d>;
				qcom,remote-pid = <0x05>;

				fastrpc {
					compatible = "qcom,fastrpc";
					qcom,glink-channels = "fastrpcglink-apps-dsp";
					label = "cdsp";
					qcom,non-secure-domain;
					#address-cells = <0x01>;
					#size-cells = <0x00>;

					compute-cb@5 {
						compatible = "qcom,fastrpc-compute-cb";
						reg = <0x05>;
						iommus = <0x95 0x03>;
					};

					compute-cb@6 {
						compatible = "qcom,fastrpc-compute-cb";
						reg = <0x06>;
						iommus = <0x95 0x04>;
					};

					compute-cb@7 {
						compatible = "qcom,fastrpc-compute-cb";
						reg = <0x07>;
						iommus = <0x95 0x05>;
					};

					compute-cb@8 {
						compatible = "qcom,fastrpc-compute-cb";
						reg = <0x08>;
						iommus = <0x95 0x06>;
					};

					compute-cb@9 {
						compatible = "qcom,fastrpc-compute-cb";
						reg = <0x09>;
						iommus = <0x95 0x07>;
					};

					compute-cb@10 {
						compatible = "qcom,fastrpc-compute-cb";
						reg = <0x0a>;
						iommus = <0x95 0x08>;
					};

					compute-cb@11 {
						compatible = "qcom,fastrpc-compute-cb";
						reg = <0x0b>;
						iommus = <0x95 0x09>;
					};

					compute-cb@12 {
						compatible = "qcom,fastrpc-compute-cb";
						reg = <0x0c>;
						iommus = <0x95 0x0a>;
					};

					compute-cb@13 {
						compatible = "qcom,fastrpc-compute-cb";
						reg = <0x0d>;
						iommus = <0x95 0x0b>;
					};
				};
			};
		};
	};

	sound {
		compatible = "qcom,sdm660-internal-sndcard";
		model = "Xiaomi Mi Pad 4";
		pinctrl-0 = <0x96 0x97>;
		pinctrl-names = "default";
		audio-routing = "RX_BIAS", "Digital MCLK", "INT_LDO_H", "Digital MCLK", "Digital RX_I2S_CLK", "Digital MCLK", "Digital TX_I2S_CLK", "Digital MCLK", "Digital ADC1", "ADC1", "Digital ADC2", "ADC2", "Digital ADC3", "ADC3", "PDM_RX1", "Digital PDM_RX1", "PDM_RX2", "Digital PDM_RX2", "PDM_RX3", "Digital PDM_RX3", "Digital LPASS_PDM_TX", "PDM_TX", "AMIC1", "MIC BIAS External1", "AMIC2", "MIC BIAS External2";

		mm1-dai-link {
			link-name = "MultiMedia1";

			cpu {
				sound-dai = <0x98 0x00>;
			};
		};

		mm2-dai-link {
			link-name = "MultiMedia2";

			cpu {
				sound-dai = <0x98 0x01>;
			};
		};

		int0-mi2s-dai-link {
			link-name = "Internal MI2S Playback";

			cpu {
				sound-dai = <0x99 0x89>;
			};

			platform {
				sound-dai = <0x9a>;
			};

			codec {
				sound-dai = <0x9b 0x00 0x9c 0x00>;
			};
		};

		int3-mi2s-dai-link {
			link-name = "Internal MI2S Capture";

			cpu {
				sound-dai = <0x99 0x90>;
			};

			platform {
				sound-dai = <0x9a>;
			};

			codec {
				sound-dai = <0x9b 0x01 0x9c 0x01>;
			};
		};
	};

	thermal-zones {

		aoss-thermal {
			polling-delay-passive = <0xfa>;
			thermal-sensors = <0x9d 0x00>;

			trips {

				trip-point0 {
					temperature = <0x19a28>;
					hysteresis = <0x3e8>;
					type = "hot";
				};
			};
		};

		cpuss0-thermal {
			polling-delay-passive = <0xfa>;
			thermal-sensors = <0x9d 0x01>;

			trips {

				trip-point0 {
					temperature = <0x1e848>;
					hysteresis = <0x3e8>;
					type = "hot";
				};
			};
		};

		cpuss1-thermal {
			polling-delay-passive = <0xfa>;
			thermal-sensors = <0x9d 0x02>;

			trips {

				trip-point0 {
					temperature = <0x1e848>;
					hysteresis = <0x3e8>;
					type = "hot";
				};
			};
		};

		cpu0-thermal {
			polling-delay-passive = <0xfa>;
			thermal-sensors = <0x9d 0x03>;

			trips {

				trip-point0 {
					temperature = <0x11170>;
					hysteresis = <0x3e8>;
					type = "passive";
				};

				cpu-crit {
					temperature = <0x1adb0>;
					hysteresis = <0x3e8>;
					type = "critical";
				};
			};
		};

		cpu1-thermal {
			polling-delay-passive = <0xfa>;
			thermal-sensors = <0x9d 0x04>;

			trips {

				trip-point0 {
					temperature = <0x11170>;
					hysteresis = <0x3e8>;
					type = "passive";
				};

				cpu-crit {
					temperature = <0x1adb0>;
					hysteresis = <0x3e8>;
					type = "critical";
				};
			};
		};

		cpu2-thermal {
			polling-delay-passive = <0xfa>;
			thermal-sensors = <0x9d 0x05>;

			trips {

				trip-point0 {
					temperature = <0x11170>;
					hysteresis = <0x3e8>;
					type = "passive";
				};

				cpu-crit {
					temperature = <0x1adb0>;
					hysteresis = <0x3e8>;
					type = "critical";
				};
			};
		};

		cpu3-thermal {
			polling-delay-passive = <0xfa>;
			thermal-sensors = <0x9d 0x06>;

			trips {

				trip-point0 {
					temperature = <0x11170>;
					hysteresis = <0x3e8>;
					type = "passive";
				};

				cpu-crit {
					temperature = <0x1adb0>;
					hysteresis = <0x3e8>;
					type = "critical";
				};
			};
		};

		pwr-cluster-thermal {
			polling-delay-passive = <0xfa>;
			thermal-sensors = <0x9d 0x07>;

			trips {

				trip-point0 {
					temperature = <0x11170>;
					hysteresis = <0x3e8>;
					type = "passive";
				};

				cpu-crit {
					temperature = <0x1adb0>;
					hysteresis = <0x3e8>;
					type = "critical";
				};
			};
		};

		gpu-thermal {
			polling-delay-passive = <0xfa>;
			thermal-sensors = <0x9d 0x08>;

			cooling-maps {

				map0 {
					trip = <0x9e>;
					cooling-device = <0x9f 0xffffffff 0xffffffff>;
				};
			};

			trips {

				trip-point0 {
					temperature = <0x14c08>;
					hysteresis = <0x3e8>;
					type = "passive";
					phandle = <0x9e>;
				};

				trip-point1 {
					temperature = <0x15f90>;
					hysteresis = <0x3e8>;
					type = "hot";
				};

				trip-point2 {
					temperature = <0x1adb0>;
					hysteresis = <0x3e8>;
					type = "critical";
				};
			};
		};

		pm660-thermal {
			polling-delay-passive = <0xfa>;
			thermal-sensors = <0xa0>;

			trips {

				pm660-alert0 {
					temperature = <0x17318>;
					hysteresis = <0x7d0>;
					type = "passive";
				};

				pm660-crit {
					temperature = <0x1e848>;
					hysteresis = <0x7d0>;
					type = "critical";
				};
			};
		};

		pm660l-thermal {
			polling-delay-passive = <0xfa>;
			thermal-sensors = <0xa1>;

			trips {

				pm660l-alert0 {
					temperature = <0x17318>;
					hysteresis = <0x7d0>;
					type = "passive";
				};

				pm660l-crit {
					temperature = <0x1e848>;
					hysteresis = <0x7d0>;
					type = "critical";
				};
			};
		};
	};

	timer {
		compatible = "arm,armv8-timer";
		interrupts = <0x01 0x01 0xf08 0x01 0x02 0xf08 0x01 0x03 0xf08 0x01 0x00 0xf08>;
	};

	smp2p-cdsp {
		compatible = "qcom,smp2p";
		qcom,smem = <0x5e 0x1b0>;
		interrupts = <0x00 0x202 0x01>;
		mboxes = <0x1c 0x1e>;
		qcom,local-pid = <0x00>;
		qcom,remote-pid = <0x05>;

		master-kernel {
			qcom,entry-name = "master-kernel";
			#qcom,smem-state-cells = <0x01>;
			phandle = <0x94>;
		};

		slave-kernel {
			qcom,entry-name = "slave-kernel";
			interrupt-controller;
			#interrupt-cells = <0x02>;
			phandle = <0x92>;
		};
	};

	lcd-power-regulator {
		compatible = "regulator-fixed";
		regulator-name = "lcd_pwr";
		regulator-min-microvolt = <0x325aa0>;
		regulator-max-microvolt = <0x325aa0>;
		gpio = <0x3b 0x05 0x00>;
		enable-active-high;
		pinctrl-names = "default";
		pinctrl-0 = <0xa2>;
		phandle = <0x5e>;
	};

	vph-pwr-regulator {
		compatible = "regulator-fixed";
		regulator-name = "vph_pwr";
		regulator-always-on;
		regulator-boot-on;
		phandle = <0x1e>;
	};

	gpio-keys {
		compatible = "gpio-keys";
		pinctrl-0 = <0xa3>;
		pinctrl-names = "default";

		key-volup {
			label = "Volume Up";
			gpios = <0x3b 0x07 0x01>;
			linux,code = <0x73>;
			debounce-interval = <0x0f>;
		};
	};

	gpio-hall-sensor {
		compatible = "gpio-keys";
		pinctrl-0 = <0xa4>;
		pinctrl-names = "default";

		switch {
			label = "Hall Effect Sensor";
			gpios = <0x29 0x4b 0x01>;
			linux,input-type = <0x05>;
			linux,code = <0x00>;
			linux,can-disable;
			wakeup-source;
		};
	};

	battery {
		compatible = "simple-battery";
		device-chemistry = "lithium-ion";
		charge-full-design-microamp-hours = <0x5bb490>;
		voltage-min-design-microvolt = <0x33e140>;
		voltage-max-design-microvolt = <0x432380>;
		phandle = <0x37>;
	};
};
